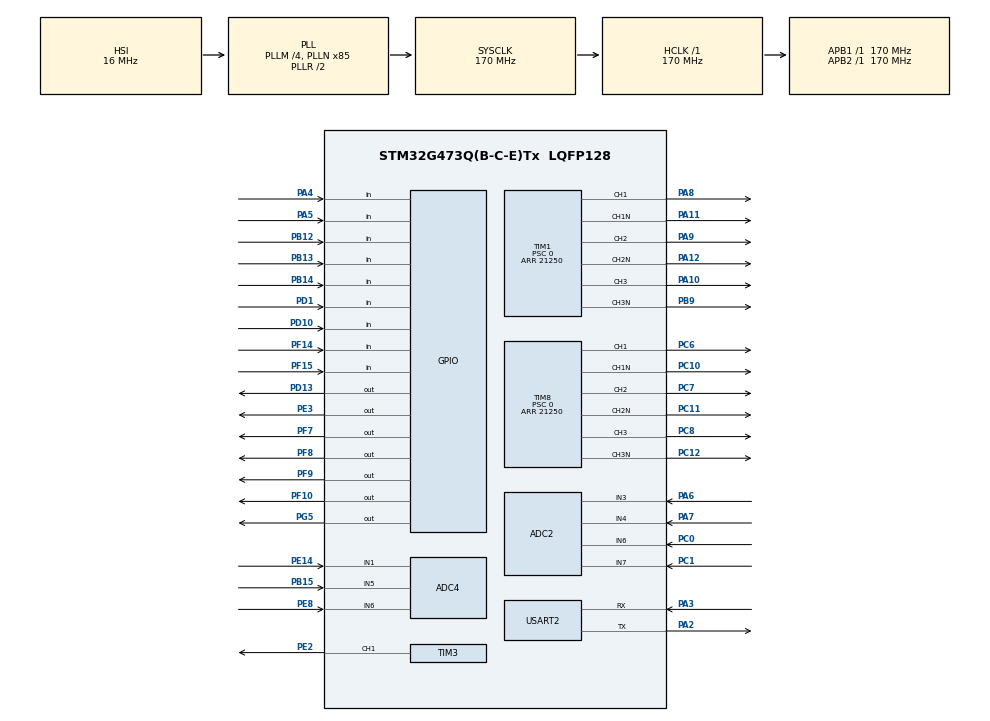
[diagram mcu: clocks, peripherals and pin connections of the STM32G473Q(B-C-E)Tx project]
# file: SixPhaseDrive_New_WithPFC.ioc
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ADC2.DMAContinuousRequests=DISABLE
ADC2.EOCSelection=ADC_EOC_SINGLE_CONV
ADC2.EnableInjectedConversion=ENABLE
ADC2.EnableRegularConversion=DISABLE
ADC2.ExternalTrigInjecConv=ADC_EXTERNALTRIGINJEC_T1_TRGO
ADC2.InjNumberOfConversion=4
ADC2.InjectedChannel-10\#ChannelInjectedConversion=ADC_CHANNEL_3
ADC2.InjectedChannel-11\#ChannelInjectedConversion=ADC_CHANNEL_7
ADC2.InjectedChannel-12\#ChannelInjectedConversion=ADC_CHANNEL_4
ADC2.InjectedChannel-9\#ChannelInjectedConversion=ADC_CHANNEL_6
ADC2.InjectedOffsetNumber-10\#ChannelInjectedConversion=ADC_OFFSET_NONE
ADC2.InjectedOffsetNumber-11\#ChannelInjectedConversion=ADC_OFFSET_NONE
ADC2.InjectedOffsetNumber-12\#ChannelInjectedConversion=ADC_OFFSET_NONE
ADC2.InjectedOffsetNumber-9\#ChannelInjectedConversion=ADC_OFFSET_NONE
ADC2.InjectedRank-10\#ChannelInjectedConversion=2
ADC2.InjectedRank-11\#ChannelInjectedConversion=3
ADC2.InjectedRank-12\#ChannelInjectedConversion=4
ADC2.InjectedRank-9\#ChannelInjectedConversion=1
ADC2.InjectedSamplingTime-10\#ChannelInjectedConversion=ADC_SAMPLETIME_6CYCLES_5
ADC2.InjectedSamplingTime-11\#ChannelInjectedConversion=ADC_SAMPLETIME_6CYCLES_5
ADC2.InjectedSamplingTime-12\#ChannelInjectedConversion=ADC_SAMPLETIME_6CYCLES_5
ADC2.InjectedSamplingTime-9\#ChannelInjectedConversion=ADC_SAMPLETIME_6CYCLES_5
ADC2.Rank4_Channel=ADC_CHANNEL_4
ADC4.Channel-0\#ChannelRegularConversion=ADC_CHANNEL_5
ADC4.Channel-1\#ChannelRegularConversion=ADC_CHANNEL_6
ADC4.Channel-2\#ChannelRegularConversion=ADC_CHANNEL_1
ADC4.DMAContinuousRequests=ENABLE
ADC4.EOCSelection=ADC_EOC_SEQ_CONV
ADC4.ExternalTrigConv=ADC_EXTERNALTRIG_T4_TRGO
ADC4.ExternalTrigConvEdge=ADC_EXTERNALTRIGCONVEDGE_FALLING
ADC4.NbrOfConversion=3
ADC4.NbrOfConversionFlag=1
ADC4.OffsetNumber-0\#ChannelRegularConversion=ADC_OFFSET_NONE
ADC4.OffsetNumber-1\#ChannelRegularConversion=ADC_OFFSET_NONE
ADC4.OffsetNumber-2\#ChannelRegularConversion=ADC_OFFSET_NONE
ADC4.Overrun=ADC_OVR_DATA_OVERWRITTEN
ADC4.Rank-0\#ChannelRegularConversion=1
ADC4.Rank-1\#ChannelRegularConversion=2
ADC4.Rank-2\#ChannelRegularConversion=3
ADC4.SamplingTime-0\#ChannelRegularConversion=ADC_SAMPLETIME_12CYCLES_5
ADC4.SamplingTime-1\#ChannelRegularConversion=ADC_SAMPLETIME_12CYCLES_5
ADC4.SamplingTime-2\#ChannelRegularConversion=ADC_SAMPLETIME_12CYCLES_5
Dma.ADC4.0.Direction=DMA_PERIPH_TO_MEMORY
Dma.ADC4.0.EventEnable=DISABLE
Dma.ADC4.0.Instance=DMA1_Channel2
Dma.ADC4.0.MemDataAlignment=DMA_MDATAALIGN_HALFWORD
Dma.ADC4.0.MemInc=DMA_MINC_ENABLE
Dma.ADC4.0.Mode=DMA_CIRCULAR
Dma.ADC4.0.PeriphDataAlignment=DMA_PDATAALIGN_HALFWORD
Dma.ADC4.0.PeriphInc=DMA_PINC_DISABLE
Dma.ADC4.0.Polarity=HAL_DMAMUX_REQ_GEN_RISING
Dma.ADC4.0.Priority=DMA_PRIORITY_VERY_HIGH
Dma.ADC4.0.RequestNumber=1
Dma.ADC4.0.SignalID=NONE
Dma.ADC4.0.SyncEnable=DISABLE
Dma.ADC4.0.SyncPolarity=HAL_DMAMUX_SYNC_NO_EVENT
Dma.ADC4.0.SyncRequestNumber=1
Dma.ADC4.0.SyncSignalID=NONE
Dma.Request0=ADC4
Mcu.Family=STM32G4
Mcu.Name=STM32G473Q(B-C-E)Tx
Mcu.Package=LQFP128
NVIC.ADC1_2_IRQn=true\:3\:0\:true\:true\:true\:2\:true\:true\:true
NVIC.DMA1_Channel2_IRQn=true\:0\:0\:false\:false\:true\:false\:true\:true
NVIC.PriorityGroup=NVIC_PRIORITYGROUP_4
NVIC.TIM1_UP_TIM16_IRQn=true\:2\:0\:true\:true\:true\:1\:true\:true\:true
NVIC.TIM4_IRQn=true\:0\:0\:true\:false\:true\:true\:true\:true
PA10.Signal=S_TIM1_CH3
PA11.Mode=PWM Generation1 CH1 CH1N
PA11.Signal=TIM1_CH1N
PA12.Mode=PWM Generation2 CH2 CH2N
PA12.Signal=TIM1_CH2N
PA13.Mode=Serial_Wire
PA13.Signal=SYS_JTMS-SWDIO
PA14.Mode=Serial_Wire
PA14.Signal=SYS_JTCK-SWCLK
PA2.Mode=Asynchronous
PA2.Signal=USART2_TX
PA3.Mode=Asynchronous
PA3.Signal=USART2_RX
PA4.Signal=GPIO_Input
PA5.Signal=GPIO_Input
PA6.Mode=IN3-Single-Ended
PA6.Signal=ADC2_IN3
PA7.Mode=IN4-Single-Ended
PA7.Signal=ADC2_IN4
PA8.Signal=S_TIM1_CH1
PA9.Signal=S_TIM1_CH2
PB12.Signal=GPIO_Input
PB13.Signal=GPIO_Input
PB14.Signal=GPIO_Input
PB15.Mode=IN5-Single-Ended
PB15.Signal=ADC4_IN5
PB9.Mode=PWM Generation3 CH3 CH3N
PB9.Signal=TIM1_CH3N
PC0.Mode=IN6-Single-Ended
PC0.Signal=ADC2_IN6
PC1.Mode=IN7-Single-Ended
PC1.Signal=ADC2_IN7
PC10.Mode=PWM Generation1 CH1 CH1N
PC10.Signal=TIM8_CH1N
PC11.Mode=PWM Generation2 CH2 CH2N
PC11.Signal=TIM8_CH2N
PC12.Mode=PWM Generation3 CH3 CH3N
PC12.Signal=TIM8_CH3N
PC14-OSC32_IN.Mode=LSE-External-Oscillator
PC14-OSC32_IN.Signal=RCC_OSC32_IN
PC15-OSC32_OUT.Mode=LSE-External-Oscillator
PC15-OSC32_OUT.Signal=RCC_OSC32_OUT
PC6.Signal=S_TIM8_CH1
PC7.Signal=S_TIM8_CH2
PC8.Signal=S_TIM8_CH3
PD1.Signal=GPIO_Input
PD10.Signal=GPIO_Input
PD13.Signal=GPIO_Output
PE14.Mode=IN1-Single-Ended
PE14.Signal=ADC4_IN1
PE2.Signal=S_TIM3_CH1
PE3.Signal=GPIO_Output
PE8.Mode=IN6-Single-Ended
PE8.Signal=ADC4_IN6
PF0-OSC_IN.Mode=HSE-External-Oscillator
PF0-OSC_IN.Signal=RCC_OSC_IN
PF1-OSC_OUT.Mode=HSE-External-Oscillator
PF1-OSC_OUT.Signal=RCC_OSC_OUT
PF10.Signal=GPIO_Output
PF14.Signal=GPIO_Input
PF15.Signal=GPIO_Input
PF7.Signal=GPIO_Output
PF8.Signal=GPIO_Output
PF9.Signal=GPIO_Output
PG5.Signal=GPIO_Output
ProjectManager.HeapSize=0x200
ProjectManager.StackSize=0x400
ProjectManager.TargetToolchain=STM32CubeIDE
RCC.ADC12Freq_Value=170000000
RCC.ADC345Freq_Value=170000000
RCC.AHBFreq_Value=170000000
RCC.APB1Freq_Value=170000000
RCC.APB1TimFreq_Value=170000000
RCC.APB2Freq_Value=170000000
RCC.APB2TimFreq_Value=170000000
RCC.CortexFreq_Value=170000000
RCC.EXTERNAL_CLOCK_VALUE=12288000
RCC.HCLKFreq_Value=170000000
RCC.HSE_VALUE=24000000
RCC.HSI48_VALUE=48000000
RCC.HSI_VALUE=16000000
RCC.PLLM=RCC_PLLM_DIV4
RCC.PLLN=85
RCC.SYSCLKFreq_VALUE=170000000
RCC.SYSCLKSource=RCC_SYSCLKSOURCE_PLLCLK
RCC.USBFreq_Value=170000000
RCC.VCOOutputFreq_Value=340000000
SH.S_TIM1_CH1.0=TIM1_CH1,PWM Generation1 CH1 CH1N
SH.S_TIM1_CH2.0=TIM1_CH2,PWM Generation2 CH2 CH2N
SH.S_TIM1_CH3.0=TIM1_CH3,PWM Generation3 CH3 CH3N
SH.S_TIM3_CH1.0=TIM3_CH1,PWM Generation1 CH1
SH.S_TIM8_CH1.0=TIM8_CH1,PWM Generation1 CH1 CH1N
SH.S_TIM8_CH2.0=TIM8_CH2,PWM Generation2 CH2 CH2N
SH.S_TIM8_CH3.0=TIM8_CH3,PWM Generation3 CH3 CH3N
TIM1.Channel-PWM\ Generation1\ CH1\ CH1N=TIM_CHANNEL_1
TIM1.Channel-PWM\ Generation2\ CH2\ CH2N=TIM_CHANNEL_2
TIM1.Channel-PWM\ Generation3\ CH3\ CH3N=TIM_CHANNEL_3
TIM1.CounterMode=TIM_COUNTERMODE_CENTERALIGNED3
TIM1.DeadTime=170
TIM1.OCMode_PWM-PWM\ Generation1\ CH1\ CH1N=TIM_OCMODE_PWM1
TIM1.OCMode_PWM-PWM\ Generation2\ CH2\ CH2N=TIM_OCMODE_PWM1
TIM1.OCMode_PWM-PWM\ Generation3\ CH3\ CH3N=TIM_OCMODE_PWM1
TIM1.OCNIdleState_1=TIM_OCNIDLESTATE_RESET
TIM1.OCNIdleState_2=TIM_OCNIDLESTATE_RESET
TIM1.OCNIdleState_3=TIM_OCNIDLESTATE_RESET
TIM1.OCNPolarity_1=TIM_OCNPOLARITY_HIGH
TIM1.OCNPolarity_2=TIM_OCNPOLARITY_HIGH
TIM1.OCNPolarity_3=TIM_OCNPOLARITY_HIGH
TIM1.PeriodNoDither=21250
TIM1.Prescaler=0
TIM1.RepetitionCounter=1
TIM1.TIM_MasterOutputTrigger=TIM_TRGO_UPDATE
TIM3.Channel-PWM\ Generation1\ CH1=TIM_CHANNEL_1
TIM3.PeriodNoDither=2297
TIM3.TIM_MasterOutputTrigger=TIM_TRGO_UPDATE
TIM4.Channel-PWM\ Generation1\ No\ Output=TIM_CHANNEL_1
TIM4.PeriodNoDither=2297
TIM4.Prescaler=3
TIM4.TIM_MasterOutputTrigger=TIM_TRGO_UPDATE
TIM8.Channel-PWM\ Generation1\ CH1\ CH1N=TIM_CHANNEL_1
TIM8.Channel-PWM\ Generation2\ CH2\ CH2N=TIM_CHANNEL_2
TIM8.Channel-PWM\ Generation3\ CH3\ CH3N=TIM_CHANNEL_3
TIM8.CounterMode=TIM_COUNTERMODE_CENTERALIGNED3
TIM8.DeadTime=170
TIM8.OCIdleState_3=TIM_OCIDLESTATE_RESET
TIM8.OCMode_PWM-PWM\ Generation1\ CH1\ CH1N=TIM_OCMODE_PWM1
TIM8.OCMode_PWM-PWM\ Generation2\ CH2\ CH2N=TIM_OCMODE_PWM1
TIM8.OCMode_PWM-PWM\ Generation3\ CH3\ CH3N=TIM_OCMODE_PWM1
TIM8.OCNIdleState_1=TIM_OCNIDLESTATE_RESET
TIM8.OCNIdleState_2=TIM_OCNIDLESTATE_RESET
TIM8.OCNIdleState_3=TIM_OCNIDLESTATE_RESET
TIM8.OCNPolarity_1=TIM_OCNPOLARITY_HIGH
TIM8.OCNPolarity_2=TIM_OCNPOLARITY_HIGH
TIM8.OCNPolarity_3=TIM_OCNPOLARITY_HIGH
TIM8.PeriodNoDither=21250
TIM8.Prescaler=0
TIM8.RepetitionCounter=1
TIM8.TIM_MasterOutputTrigger=TIM_TRGO_UPDATE
USART2.VirtualMode-Asynchronous=VM_ASYNC
VP_SYS_VS_DBSignals.Mode=DisableDeadBatterySignals
VP_TIM1_VS_ClockSourceINT.Mode=Internal
VP_TIM3_VS_ClockSourceINT.Mode=Internal
VP_TIM4_VS_ClockSourceINT.Mode=Internal
VP_TIM4_VS_no_output1.Mode=PWM Generation1 No Output
VP_TIM8_VS_ClockSourceITR.Mode=TriggerSource_ITR0
VP_TIM8_VS_ControllerModeTrigger.Mode=Trigger Mode
board=custom

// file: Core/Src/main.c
/* USER CODE BEGIN Header */
/**
  ******************************************************************************
  * @file           : main.c
  * @brief          : Main program body
  ******************************************************************************
  * @attention
  *
  * Copyright (c) 2024 STMicroelectronics.
  * All rights reserved.
  *
  * This software is licensed under terms that can be found in the LICENSE file
  * in the root directory of this software component.
  * If no LICENSE file comes with this software, it is provided AS-IS.
  *
  ******************************************************************************
  */
/* USER CODE END Header */
#include "main.h"

/* USER CODE BEGIN Includes */
#include <string.h>
#include <math.h>
#include <stdlib.h>
#include <clarke.h>
#include <vsd.h>
#include <ivsd.h>
#include <ipark.h>
#include <park.h>
#include <ramp_gen.h>
#include <rampctrl.h>
#include <svgen.h>
#include <Vhz_profile.h>
#include <pid.h>
#include <piq.h>
#include <pi.h>
#include <pi_spd.h>
#include <PhaseVoltage.h>
#include <DataLogger.h>
#include <fluxObs.h>
#include <fluxObs_const.h>
#include <speed_est.h>
#include <speed_const.h>
#include "PFC_control.h"

/* USER CODE END Includes */

/* USER CODE BEGIN PD */
#define TBPRD_PWM 21250                       // 10 kHz        Up-down count mode for TIM1 with controlling the PWM.
#define HALF_TBPRD_PWM 10625                  // 10 kHz
#define Fs 4000                             // Switching frequency
#define T 0.00025                             // Sampling Period
#define PI 3.14159265358979
#define Oneby2PI 0.15915494

#define VBASE 		380                           // Base Voltage : Vdc/sqrt(3)
#define IBASE 		10                            // Base Current
#define FBASE 		100                           // Base Frequency
#define INV_FBASE 	0.01                           // 1/FBASE
#define INV_IBASE   0.1                           // 1/IBASE

#define RS 			1.15                               // Stator resistance
#define RR 			1.20                               // Rotor Resistance
#define LS 			0.114                             // Stator Inductance
#define LR 			0.114                             // Rotor Inductance
#define LM 			0.105                             // Magnetizing Inductance
#define POLES   	6

//#define RS 			2.5                               // Stator resistance
//#define RR 			1.31                               // Rotor Resistance
//#define LS 			0.265                             // Stator Inductance
//#define LR 			0.265                             // Rotor Inductance
//#define LM 			0.256                             // Magnetizing Inductance
//#define POLES   	4

#define IBUFF_SIZE 1000
#define FBUFF_SIZE 1000

#define MODE_1 1                 // Double Scalar Control
#define MODE_2 2                 // VSD Scalar Control
#define MODE_3 3                 // Dual Vector Control
#define MODE_4 4                 // VSD Control
#define MODE_5 5                 // Dual I/F Control
#define MODE_6 6                 // VSD  I/F Control

#define MODE MODE_1

#ifndef MODE
#error Define MODE OF OPERATION!!!
#endif

/* USER CODE END PD */

ADC_HandleTypeDef hadc2;
ADC_HandleTypeDef hadc4;
DMA_HandleTypeDef hdma_adc4;

TIM_HandleTypeDef htim1;
TIM_HandleTypeDef htim3;
TIM_HandleTypeDef htim4;
TIM_HandleTypeDef htim8;

UART_HandleTypeDef huart2;

/* USER CODE BEGIN PV */
uint32_t ADC2_buffer[4];   // Motor Phase Currents

volatile uint16_t Inj_A1 = 0;
volatile uint16_t Inj_B1 = 0;
volatile uint16_t Inj_A2 = 0;
volatile uint16_t Inj_B2 = 0;

DATA_LOG_4CH_INT dLogInt;
DATA_LOG_4CH_FLOAT dLogFloat;
int16_t iBuff1[IBUFF_SIZE];
int16_t iBuff2[IBUFF_SIZE];
int16_t iBuff3[IBUFF_SIZE];
int16_t iBuff4[IBUFF_SIZE];
float fBuff1[FBUFF_SIZE];
float fBuff2[FBUFF_SIZE];
float fBuff3[FBUFF_SIZE];
float fBuff4[FBUFF_SIZE];
uint16_t clear_screen, print_log;

// User defined Variables
uint16_t Enable = 0;
uint16_t counter = 0;
uint16_t mode = 1;
uint16_t Activate = 0;
uint16_t SpeedLoopCount = 1;
uint16_t ClosedCurrent = 0;
uint16_t ClosedSpeed = 0;

float user_freq = 10;
float user_current = 0.5;
float mod_index = 0.1;
float mod = 1;
float Vd = 0;
float Vq = 0;
float Valpha = 0;
float Vbeta = 0;
float freq_pu = 0.0;
float F_rate_up = 0.02;
float phase_shift = PI/6;

const float TwoPI = 2.0f*M_PI;

float Trig = 1.0;

// Sensor Offsets and Gains (Calibrated Using Experiments)
float Three3VBy4095 = 0.000805 ;
float V_Offset = -1.5;
float Slope_A1 = 0.1206f ;
float Slope_B1 = 0.1218f;
float Slope_A2 = 0.1222f;
float Slope_B2 = 0.1199f;

float VDC_Slope = - 0.4032;
float VDC_Intercept = 690.37;

// Control Variables
uint32_t pwm_cnt =1;
uint32_t pfc_cnt = 1;
uint16_t pfc_control_run=0;
uint16_t enable_voltage_closed_loop=0;
uint16_t SpeedLoopPrescaler = 10;
float A1_INT,B1_INT,A2_INT,B2_INT;
float A1,B1,C1,A2,B2,C2;
float Vdc;
float Angle,Angle1,Angle2,Angle6;
float Alpha, Beta,X,Y;

float IdRef = 0.3;                            // 30 percent of nominal current
float IqRef = 0.0;

// Controller Gains
float Kpp = 0.001;
float Kii = 0.1;

float Kpx = 0.001;
float Kix = 0.1;

float Kpw = 1.0;
float Kiw = 0.0005;

//Per unit Values
float Z_base,Phi_base,L_base,W_base,R_pu,Ls_pu;

uint32_t cnt = 1;

//PFC variables
//junk

//**********************//
float Vac_filtered, Vac_RMS, VacPK_inv,Vdc_filtered, Vburst_H, Vburst_L, Vac_RMS_real;
float Vdc,IL, Vac,IA,IB,IC,NTC_temp;
float VdcRef, VdcTarget = 120, ev, DemandCurrent,DemandCurrentMAX = 1500,dVref = 0.000302265f, Vary_Vc =150.0;  // 1 corresponds to 3.7 V/s
float NTC_Precharge, Vdc_Trip, IL_Trip, IL_ref;
float ei, pwm_cmd, pwm_cmd_debug, Vc, duty_PFC;

const float IL_calibration = 1.0f;
const float Vac_calibration = 1.0f; //0.823f;
const float Vdc_calibration = 1.0f;

volatile uint16_t Vdc_INT,Vac_INT,IL_INT,IA_INT,IB_INT,IC_INT, Temp_INT, Uu_INT, Uv_INT, Uw_INT, OverCurrent_INT;
volatile uint16_t ADC4_buffer[ADC_BUF_SIZE];
volatile uint32_t ADC_buffer2[ADC_BUF_SIZE-1];

uint16_t enable_closed_loop=0;
uint16_t enable_PFC_burst_mode = 0;
uint16_t pfc_DC_control_run=0;
uint16_t pwm_cmd_uint;

int enable_OCD = 0, CurrProtection_ON = 0, VolProtection_ON = 0, prot_var = 0, NTC_locked = 0;

//*********************** PFC Controlelr gains ***************
#define Vac_b0     0.000009807882855712//0.00006092
#define Vac_b1     0.000019615765711424//0.00012184
#define Vac_b2     0.000009807882855712//0.00006092
#define Vac_a1    -1.987472984166555//-1.9751
#define Vac_a2     0.987512215697978//0.9753

// current compensator gains, NEW Current compensator
#define CI_b0      0.044365534154009
#define CI_b1      -0.018039365595791
#define CI_b2      0.001176812183666
#define CI_a1      -0.451535753739813
#define CI_a2      -0.543225583261733

//voltage compensator gains
#define CV_b0     0.107379952051721  //0.099376577815668
#define CV_b1     0.000364078028194  //0.000311711092166
#define CV_b2     -0.107015874023527 //-0.099064866723502
#define CV_a1     -1.983161391196042 //-1.9844144453917
#define CV_a2     0.983161391196042  //0.9844144453917
// Notch filter gains (50Hz)
#define Notch_b0    0.9849830  // 0.9860932
#define Notch_b1    -1.9687630 // -1.9711512
#define Notch_b2    0.9849160  // 0.9860312
#define Notch_a1    -1.9687630 // -1.9711512
#define Notch_a2    0.9698990  // 0.9721243

//***************************protection init***********************************
int Read_EARTH_Fault, Read_SC_Fault, Read_OC_Fault, Read_OnOff_Control;
int OCfault_Flag, count_SCFault, EM_Stop, count_EarthFault ;
//**************************************************************
// Display variables
extern DATA_LOG_4CH_INT dLogInt;
extern DATA_LOG_4CH_FLOAT dLogFloat;

// Initialize MACROS

RAMPGEN rg1 = RAMPGEN_DEFAULTS;
RMPCNTL rc1 = RMPCNTL_DEFAULTS;
VSD vsd1 = VSD_DEFAULTS;
IVSD ivsd1 = IVSD_DEFAULTS;
CLARKE clarke1 = CLARKE_DEFAULTS;
CLARKE clarke2 = CLARKE_DEFAULTS;
PARK   park1   = PARK_DEFAULTS;
PARK   park2   = PARK_DEFAULTS;
IPARK  ipark1  = IPARK_DEFAULTS;
IPARK  ipark2  = IPARK_DEFAULTS;
SVGEN svgen1 = SVGEN_DEFAULTS;
SVGEN svgen2 = SVGEN_DEFAULTS;
VHZPROF vhz1 = VHZPROF_DEFAULTS;
PHASEVOLTAGE volt1 = PHASEVOLTAGE_DEFAULTS;
PHASEVOLTAGE volt2 = PHASEVOLTAGE_DEFAULTS;
PI_CONTROLLER pi_id1 = PI_CONTROLLER_DEFAULTS;
PI_CONTROLLER pi_iq1 = PI_CONTROLLER_DEFAULTS;
PI_CONTROLLER pi_id2 = PI_CONTROLLER_DEFAULTS;
PI_CONTROLLER pi_iq2 = PI_CONTROLLER_DEFAULTS;
PI_CONTROLLER pi_id = PI_CONTROLLER_DEFAULTS;
PI_CONTROLLER pi_iq = PI_CONTROLLER_DEFAULTS;
PI_CONTROLLER pi_ix = PI_CONTROLLER_DEFAULTS;
PI_CONTROLLER pi_iy = PI_CONTROLLER_DEFAULTS;
PI_SPD_CONTROLLER pi_spd = PI_SPD_CONTROLLER_DEFAULTS;
FLUX_OBS flux1 = FLUXOBS_DEFAULTS;
FLUXOBS_CONST flux_const1 = FLUXOBS_CONST_DEFAULTS;
SPEEDEST speed1 = SPEEDEST_DEFAULTS;
SPEED_CONST speed_const1 = SPEED_CONST_DEFAULTS;
DF22 testDF22filter;
DF22 NotchFilter;
DF22 CurrentCompensator;
DF22 DCVoltageCompensator;

/* USER CODE END PV */

void SystemClock_Config(void);
static void MX_GPIO_Init(void);
static void MX_DMA_Init(void);
static void MX_TIM1_Init(void);
static void MX_TIM8_Init(void);
static void MX_USART2_UART_Init(void);
static void MX_ADC2_Init(void);
static void MX_TIM4_Init(void);
static void MX_TIM3_Init(void);
static void MX_ADC4_Init(void);
static void MX_NVIC_Init(void);
/* USER CODE BEGIN PFP */
void PWM_start(void);
void PWM_stop(void);
void PFC_PWM_start(void);
void PFC_PWM_stop(void);
void UARTCommands(void);
/* USER CODE END PFP */

/* USER CODE BEGIN 0 */
uint8_t buf[12];
uint8_t msg[32];
uint8_t num[6];
uint8_t TXbuffer[50];
uint8_t received;
unsigned char* msg2;
uint8_t buffer[10];
unsigned char* display_number;
float PWM_PFC_duty, duty;
uint16_t ramp_duty=0, no_fault = 0, OC_var = 1, IsRelayOn = 0, PFC_PWM = 0;
int16_t trigger=0;
float trigger_float=0;
float EM_SD_Status;
void PrintScreen(void);
void printDataLog(int16_t *DataBuffer1, int16_t *DataBuffer2, int16_t *DataBuffer3, int16_t *DataBuffer4, uint16_t dataBufferLength, uint16_t *start);
void runVDCramp(void);
void Check_OCFault(void) ;

/* USER CODE END 0 */

int main(void)
{

  /* USER CODE BEGIN 1 */
	vhz1.VoltMax = 1.0;
	vhz1.VoltMin = 0.01;
	vhz1.HighFreq = 0.9;
	vhz1.LowFreq = 0.05;
	vhz1.FreqMax = 1.0;

	rc1.Tstep = T*rc1.RampDelayMax*F_rate_up;
	rg1.StepAngleMax = FBASE*T;

// Initialize motor parameters for flux observer
	flux_const1.Rs = RS;
	flux_const1.Rr = RR;
	flux_const1.Ls = LS;
	flux_const1.Lr = LR;
	flux_const1.Lm = LM;
	flux_const1.Vb = VBASE;
	flux_const1.Ib = IBASE;
	flux_const1.Ts = T;
	FLUXOBS_CONST_MACRO(flux_const1)

// 	Initialize constants for flux observer
	flux1.K1 = flux_const1.K1;
	flux1.K2 = flux_const1.K2;
	flux1.K3 = flux_const1.K3;
	flux1.K4 = flux_const1.K4;
	flux1.K5 = flux_const1.K5;
	flux1.K6 = flux_const1.K6;
	flux1.K7 = flux_const1.K7;
	flux1.K8 = flux_const1.K8;
	flux1.Kp = 0.05;
	flux1.Ki = 0.1;

	// 	Initialize constants for speed estimation

	speed_const1.Rr = RR;
	speed_const1.Lr = LR;
	speed_const1.fb = FBASE;
	speed_const1.fc = 0.5;
	speed_const1.Ts = T;
	SPEED_CONST_MACRO(speed_const1)

	// Initialize parameters for speed estimation

	speed1.K1 = speed_const1.K1;
	speed1.K2 = speed_const1.K2;
	speed1.K3 = speed_const1.K3;
	speed1.K4 = speed_const1.K4;
	speed1.BaseRpm = 120*FBASE/POLES;

	pi_spd.Ki = Kiw;
	pi_spd.Kp = Kpw;
	pi_spd.Umax = 0.8;
	pi_spd.Umin = -0.8;

	pi_id1.Ki = Kii;
	pi_id1.Kp = Kpp;
	pi_id1.Umax = 0.8;
    pi_id1.Umin = -0.8;

    pi_iq1.Ki = Kii;
    pi_iq1.Kp = Kpp;
    pi_iq1.Umax = 0.8;
    pi_iq1.Umin = -0.8;

	pi_id2.Ki = Kii;
	pi_id2.Kp = Kpp;
	pi_id2.Umax = 0.8;
	pi_id2.Umin = -0.8;

	pi_iq2.Ki = Kii;
	pi_iq2.Kp = Kpp;
	pi_iq2.Umax = 0.8;
	pi_iq2.Umin = -0.8;

	pi_id.Ki = Kii;
	pi_id.Kp = Kpp;
	pi_id.Umax = 0.8;
    pi_id.Umin = -0.8;

    pi_iq.Ki = Kii;
    pi_iq.Kp = Kpp;
    pi_iq.Umax = 0.8;
    pi_iq.Umin = -0.8;

    pi_ix.Ki = Kix;
	pi_ix.Kp = Kpx;
	pi_ix.Umax = 0.5;
	pi_ix.Umin = -0.5;

	pi_iy.Ki = Kix;
	pi_iy.Kp = Kpx;
	pi_iy.Umax = 0.5;
	pi_iy.Umin = -0.5;

//	W_base = 2*PI*FBASE;
//	Z_base = VBASE/IBASE;
//	Phi_base = VBASE/W_base;
//	L_base = Z_base/W_base;
//	Ls_pu = Ls/L_base;
//	R_pu = Rs/Z_base;

//	pi_id1.Ki = R_pu/Ls_pu;
//	pi_id1.Kp = 0.1*Ls_pu*2*PI*Fs/15/W_base;

  // Initialize the PI module for Id
  /* USER CODE END 1 */

  /* MCU Configuration--------------------------------------------------------*/

  /* Reset of all peripherals, Initializes the Flash interface and the Systick. */
  HAL_Init();

  /* Configure the system clock */
  SystemClock_Config();

  /* Initialize all configured peripherals */
  MX_GPIO_Init();
  MX_DMA_Init();
  MX_TIM1_Init();
  MX_TIM8_Init();
  MX_USART2_UART_Init();
  MX_ADC2_Init();
  MX_TIM4_Init();
  MX_TIM3_Init();
  MX_ADC4_Init();

  /* Initialize interrupts */
  MX_NVIC_Init();
  /* USER CODE BEGIN 2 */

  DATA_LOG_4CH_FLOAT_config(&dLogFloat,
                                     &ivsd1.As1,
                                     &pi_id.Fbk,
                                     &pi_spd.Out,
                                     &pi_iq.Fbk,
   									fBuff1,
   									fBuff2,
   									fBuff3,
   									fBuff4,
   									FBUFF_SIZE,
                                       0.5,    //trigger
                                       1    // preScalar
                                       );

 DATA_LOG_4CH_INT_config(&dLogInt,
								&ivsd1.As1,
								&pi_id.Fbk,
								&pi_spd.Out,
								&pi_iq.Fbk,
								iBuff1,
								iBuff2,
								iBuff3,
								iBuff4,
								IBUFF_SIZE,
								   1, //trigger
								   1 // preScalar
								   );

 //PFC controller variables
 InitFilterDF22(&testDF22filter,Vac_b0,Vac_b1,Vac_b2,Vac_a1,Vac_a2);
 InitFilterDF22(&CurrentCompensator,CI_b0,CI_b1,CI_b2,CI_a1,CI_a2);
 InitFilterDF22(&NotchFilter,Notch_b0,Notch_b1,Notch_b2,Notch_a1,Notch_a2);
 InitFilterDF22(&DCVoltageCompensator,CV_b0,CV_b1,CV_b2,CV_a1,CV_a2);

  clear_screen=1;

  HAL_TIM_Base_Start_IT(&htim1);
 // HAL_TIM_Base_Start_IT(&htim15);
  HAL_TIM_Base_Start_IT(&htim4);

  //HAL_ADC_Start_DMA(&hadc2, ADC2_buffer, 4);
 // HAL_ADC_Start_DMA(&hadc4, ADC4_buffer, 3); //PFC

  if(HAL_OK != HAL_ADCEx_Calibration_Start(&hadc4, ADC_SINGLE_ENDED)) Error_Handler();
  if(HAL_OK != HAL_ADC_Start_DMA(&hadc4, (uint32_t*)ADC4_buffer, ADC_BUF_SIZE)) Error_Handler();//Start ADC4 with DMA

  HAL_ADCEx_InjectedStart_IT(&hadc2); // Start Motor ADC Conversion (Injected Channel, Tim1-PWM-Triggered, Interrupt Mode)

  HAL_TIM_PWM_Start(&htim1, TIM_CHANNEL_1);
  HAL_TIMEx_PWMN_Start(&htim1, TIM_CHANNEL_1);
  HAL_TIM_PWM_Start(&htim1, TIM_CHANNEL_2);
  HAL_TIMEx_PWMN_Start(&htim1, TIM_CHANNEL_2);
  HAL_TIM_PWM_Start(&htim1, TIM_CHANNEL_3);
  HAL_TIMEx_PWMN_Start(&htim1, TIM_CHANNEL_3);

  HAL_TIM_PWM_Start(&htim8, TIM_CHANNEL_1);
  HAL_TIMEx_PWMN_Start(&htim8, TIM_CHANNEL_1);
  HAL_TIM_PWM_Start(&htim8, TIM_CHANNEL_2);
  HAL_TIMEx_PWMN_Start(&htim8, TIM_CHANNEL_2);
  HAL_TIM_PWM_Start(&htim8, TIM_CHANNEL_3);
  HAL_TIMEx_PWMN_Start(&htim8, TIM_CHANNEL_3);

  /*-------------- PFC init begin----------------------------*/
  Vc=Vary_Vc ;
  VdcRef=90.0f;
//  VdcTarget_init=120 ; //380.0f;
  IL_Trip = -30;
  //dVref=1.0f; // VDC ramp rate
 // DemandCurrentMAX=1500;        //9500.0;
  NTC_Precharge = 250.0; // 250dc-150V forNTC
  Vdc_Trip = 350.0;
  Vburst_H = 400.0;
  Vburst_L = 370.0;
  enable_closed_loop=0;
  enable_voltage_closed_loop=0;
  /*-------------- PFC init end----------------------------*/

  //****************** GPIO settings for protection *************************
  HAL_GPIO_WritePin(GPIOD, GPIO_PIN_13, GPIO_PIN_SET);   //PD13- EM_STOP_SD - high for IPM to be on, if low then its fault
  HAL_GPIO_WritePin(GPIOD, GPIO_PIN_1, GPIO_PIN_RESET);  // OC_fault
  HAL_GPIO_WritePin(GPIOF, GPIO_PIN_14, GPIO_PIN_RESET); // SC_fault
  HAL_GPIO_WritePin(GPIOF, GPIO_PIN_15, GPIO_PIN_RESET); // Earth_fault
  HAL_GPIO_WritePin(GPIOD, GPIO_PIN_10, GPIO_PIN_RESET);  // on off

  /* USER CODE END 2 */

  /* Infinite loop */
  while (1)
  {

    /* USER CODE BEGIN 3 */

	    pi_spd.Ki = Kiw; 	pi_spd.Kp = Kpw;

		pi_id1.Ki = Kii; 	pi_id1.Kp = Kpp;
		pi_iq1.Ki = Kii; 	pi_iq1.Kp = Kpp;

		pi_id2.Ki = Kii; 	pi_id2.Kp = Kpp;
		pi_iq2.Ki = Kii; 	pi_iq2.Kp = Kpp;

		pi_id.Ki = Kii;		pi_id.Kp = Kpp;
		pi_iq.Ki = Kii;		pi_iq.Kp = Kpp;

		pi_ix.Ki = Kix;		pi_ix.Kp = Kpx;
		pi_iy.Ki = Kix;		pi_iy.Kp = Kpp;

	  if(print_log)
	 	 {
	 	  	printDataLog(iBuff1, iBuff2, iBuff3, iBuff4, IBUFF_SIZE, &print_log);
	 	 }
	 else PrintScreen();

/*-------------- PFC init begin----------------------------*/
	//  if((Vdc>NTC_Precharge/*2376*/) && (NTC_locked == 0)) // relay threshold for bypassing relay in PFC
	  if(IsRelayOn == 1)
	  {
		  HAL_GPIO_WritePin(GPIOE, GPIO_PIN_3, GPIO_PIN_SET); //PE3 - input for NTC, LED off
		  ramp_duty=1;
		//  HAL_Delay(20);
		  NTC_locked = 1;
	  }
	  else
	  {
		  HAL_GPIO_WritePin(GPIOE, GPIO_PIN_3, GPIO_PIN_RESET); //LED ON
	  }
	 // else if (Vdc<150.0f/*1944*/)
//	  {
//		  HAL_GPIO_WritePin(GPIOE, GPIO_PIN_3, GPIO_PIN_RESET);
//		//  duty=0;   // uncomment this for real proto
//		  ramp_duty=0;
//	  }

	  PWM_PFC_duty = (duty*2297.0f);// use constant instead of 2125.0f
	  if(enable_closed_loop==0) __HAL_TIM_SetCompare(&htim3,TIM_CHANNEL_1,PWM_PFC_duty);

//	  if(PFC_PWM == 1)
//	  {
//		  PFC_PWM_start();
//	  }
//	  else PFC_PWM_stop();

	  /*-------------- protections ----------------------------*/
	   Check_OCFault() ; //OC fault detection

////PD10 for on off control
	  Read_OnOff_Control = HAL_GPIO_ReadPin(GPIOD, GPIO_PIN_10) ; // 1- on off switch is off, 0-on off switch is on

//	  if (Read_OnOff_Control == 1)
//	  {
//		  PWM_stop();  //MCU stops PWM
//	  }

	  //enable this to test fault
	  if (EM_Stop)
	  {
		  HAL_GPIO_WritePin(GPIOD, GPIO_PIN_13, GPIO_PIN_RESET); //IPM_stops here
	  }

	  /*-------------- protection end ----------------------------*/

	  UARTCommands();

	  if(Vac_RMS>30.0) VacPK_inv= 0.5/Vac_RMS;//0.707106781/Vac_RMS;
/*-------------- PFC init end----------------------------*/

	 HAL_Delay(300);

  }
  /* USER CODE END 3 */
}

void SystemClock_Config(void)
{
  RCC_OscInitTypeDef RCC_OscInitStruct = {0};
  RCC_ClkInitTypeDef RCC_ClkInitStruct = {0};

  /** Configure the main internal regulator output voltage
  */
  HAL_PWREx_ControlVoltageScaling(PWR_REGULATOR_VOLTAGE_SCALE1_BOOST);

  /** Initializes the RCC Oscillators according to the specified parameters
  * in the RCC_OscInitTypeDef structure.
  */
  RCC_OscInitStruct.OscillatorType = RCC_OSCILLATORTYPE_HSI;
  RCC_OscInitStruct.HSIState = RCC_HSI_ON;
  RCC_OscInitStruct.HSICalibrationValue = RCC_HSICALIBRATION_DEFAULT;
  RCC_OscInitStruct.PLL.PLLState = RCC_PLL_ON;
  RCC_OscInitStruct.PLL.PLLSource = RCC_PLLSOURCE_HSI;
  RCC_OscInitStruct.PLL.PLLM = RCC_PLLM_DIV4;
  RCC_OscInitStruct.PLL.PLLN = 85;
  RCC_OscInitStruct.PLL.PLLP = RCC_PLLP_DIV2;
  RCC_OscInitStruct.PLL.PLLQ = RCC_PLLQ_DIV2;
  RCC_OscInitStruct.PLL.PLLR = RCC_PLLR_DIV2;
  if (HAL_RCC_OscConfig(&RCC_OscInitStruct) != HAL_OK)
  {
    Error_Handler();
  }

  /** Initializes the CPU, AHB and APB buses clocks
  */
  RCC_ClkInitStruct.ClockType = RCC_CLOCKTYPE_HCLK|RCC_CLOCKTYPE_SYSCLK
                              |RCC_CLOCKTYPE_PCLK1|RCC_CLOCKTYPE_PCLK2;
  RCC_ClkInitStruct.SYSCLKSource = RCC_SYSCLKSOURCE_PLLCLK;
  RCC_ClkInitStruct.AHBCLKDivider = RCC_SYSCLK_DIV1;
  RCC_ClkInitStruct.APB1CLKDivider = RCC_HCLK_DIV1;
  RCC_ClkInitStruct.APB2CLKDivider = RCC_HCLK_DIV1;

  if (HAL_RCC_ClockConfig(&RCC_ClkInitStruct, FLASH_LATENCY_4) != HAL_OK)
  {
    Error_Handler();
  }
}

/**
  * @brief NVIC Configuration.
  * @retval None
  */
static void MX_NVIC_Init(void)
{
  /* TIM1_UP_TIM16_IRQn interrupt configuration */
  HAL_NVIC_SetPriority(TIM1_UP_TIM16_IRQn, 2, 0);
  HAL_NVIC_EnableIRQ(TIM1_UP_TIM16_IRQn);
  /* ADC1_2_IRQn interrupt configuration */
  HAL_NVIC_SetPriority(ADC1_2_IRQn, 3, 0);
  HAL_NVIC_EnableIRQ(ADC1_2_IRQn);
}

static void MX_ADC2_Init(void)
{

  ADC_InjectionConfTypeDef sConfigInjected = {0};

  /** Common config
  */
  hadc2.Instance = ADC2;
  hadc2.Init.ClockPrescaler = ADC_CLOCK_SYNC_PCLK_DIV4;
  hadc2.Init.Resolution = ADC_RESOLUTION_12B;
  hadc2.Init.DataAlign = ADC_DATAALIGN_RIGHT;
  hadc2.Init.GainCompensation = 0;
  hadc2.Init.ScanConvMode = ADC_SCAN_ENABLE;
  hadc2.Init.EOCSelection = ADC_EOC_SINGLE_CONV;
  hadc2.Init.LowPowerAutoWait = DISABLE;
  hadc2.Init.ContinuousConvMode = DISABLE;
  hadc2.Init.NbrOfConversion = 1;
  hadc2.Init.DiscontinuousConvMode = DISABLE;
  hadc2.Init.DMAContinuousRequests = DISABLE;
  hadc2.Init.Overrun = ADC_OVR_DATA_PRESERVED;
  hadc2.Init.OversamplingMode = DISABLE;
  if (HAL_ADC_Init(&hadc2) != HAL_OK)
  {
    Error_Handler();
  }

  /** Configure Injected Channel
  */
  sConfigInjected.InjectedChannel = ADC_CHANNEL_6;
  sConfigInjected.InjectedRank = ADC_INJECTED_RANK_1;
  sConfigInjected.InjectedSamplingTime = ADC_SAMPLETIME_6CYCLES_5;
  sConfigInjected.InjectedSingleDiff = ADC_SINGLE_ENDED;
  sConfigInjected.InjectedOffsetNumber = ADC_OFFSET_NONE;
  sConfigInjected.InjectedOffset = 0;
  sConfigInjected.InjectedNbrOfConversion = 4;
  sConfigInjected.InjectedDiscontinuousConvMode = DISABLE;
  sConfigInjected.AutoInjectedConv = DISABLE;
  sConfigInjected.QueueInjectedContext = DISABLE;
  sConfigInjected.ExternalTrigInjecConv = ADC_EXTERNALTRIGINJEC_T1_TRGO;
  sConfigInjected.ExternalTrigInjecConvEdge = ADC_EXTERNALTRIGINJECCONV_EDGE_RISING;
  sConfigInjected.InjecOversamplingMode = DISABLE;
  if (HAL_ADCEx_InjectedConfigChannel(&hadc2, &sConfigInjected) != HAL_OK)
  {
    Error_Handler();
  }

  /** Configure Injected Channel
  */
  sConfigInjected.InjectedChannel = ADC_CHANNEL_3;
  sConfigInjected.InjectedRank = ADC_INJECTED_RANK_2;
  if (HAL_ADCEx_InjectedConfigChannel(&hadc2, &sConfigInjected) != HAL_OK)
  {
    Error_Handler();
  }

  /** Configure Injected Channel
  */
  sConfigInjected.InjectedChannel = ADC_CHANNEL_7;
  sConfigInjected.InjectedRank = ADC_INJECTED_RANK_3;
  if (HAL_ADCEx_InjectedConfigChannel(&hadc2, &sConfigInjected) != HAL_OK)
  {
    Error_Handler();
  }

  /** Configure Injected Channel
  */
  sConfigInjected.InjectedChannel = ADC_CHANNEL_4;
  sConfigInjected.InjectedRank = ADC_INJECTED_RANK_4;
  if (HAL_ADCEx_InjectedConfigChannel(&hadc2, &sConfigInjected) != HAL_OK)
  {
    Error_Handler();
  }

}

static void MX_ADC4_Init(void)
{

  ADC_ChannelConfTypeDef sConfig = {0};

  /** Common config
  */
  hadc4.Instance = ADC4;
  hadc4.Init.ClockPrescaler = ADC_CLOCK_SYNC_PCLK_DIV4;
  hadc4.Init.Resolution = ADC_RESOLUTION_12B;
  hadc4.Init.DataAlign = ADC_DATAALIGN_RIGHT;
  hadc4.Init.GainCompensation = 0;
  hadc4.Init.ScanConvMode = ADC_SCAN_ENABLE;
  hadc4.Init.EOCSelection = ADC_EOC_SEQ_CONV;
  hadc4.Init.LowPowerAutoWait = DISABLE;
  hadc4.Init.ContinuousConvMode = DISABLE;
  hadc4.Init.NbrOfConversion = 3;
  hadc4.Init.DiscontinuousConvMode = DISABLE;
  hadc4.Init.ExternalTrigConv = ADC_EXTERNALTRIG_T4_TRGO;
  hadc4.Init.ExternalTrigConvEdge = ADC_EXTERNALTRIGCONVEDGE_FALLING;
  hadc4.Init.DMAContinuousRequests = ENABLE;
  hadc4.Init.Overrun = ADC_OVR_DATA_OVERWRITTEN;
  hadc4.Init.OversamplingMode = DISABLE;
  if (HAL_ADC_Init(&hadc4) != HAL_OK)
  {
    Error_Handler();
  }

  /** Configure Regular Channel
  */
  sConfig.Channel = ADC_CHANNEL_5;
  sConfig.Rank = ADC_REGULAR_RANK_1;
  sConfig.SamplingTime = ADC_SAMPLETIME_12CYCLES_5;
  sConfig.SingleDiff = ADC_SINGLE_ENDED;
  sConfig.OffsetNumber = ADC_OFFSET_NONE;
  sConfig.Offset = 0;
  if (HAL_ADC_ConfigChannel(&hadc4, &sConfig) != HAL_OK)
  {
    Error_Handler();
  }

  /** Configure Regular Channel
  */
  sConfig.Channel = ADC_CHANNEL_6;
  sConfig.Rank = ADC_REGULAR_RANK_2;
  if (HAL_ADC_ConfigChannel(&hadc4, &sConfig) != HAL_OK)
  {
    Error_Handler();
  }

  /** Configure Regular Channel
  */
  sConfig.Channel = ADC_CHANNEL_1;
  sConfig.Rank = ADC_REGULAR_RANK_3;
  if (HAL_ADC_ConfigChannel(&hadc4, &sConfig) != HAL_OK)
  {
    Error_Handler();
  }

}

static void MX_TIM1_Init(void)
{

  TIM_ClockConfigTypeDef sClockSourceConfig = {0};
  TIM_MasterConfigTypeDef sMasterConfig = {0};
  TIM_OC_InitTypeDef sConfigOC = {0};
  TIM_BreakDeadTimeConfigTypeDef sBreakDeadTimeConfig = {0};

  htim1.Instance = TIM1;
  htim1.Init.Prescaler = 0;
  htim1.Init.CounterMode = TIM_COUNTERMODE_CENTERALIGNED3;
  htim1.Init.Period = 21250;
  htim1.Init.ClockDivision = TIM_CLOCKDIVISION_DIV1;
  htim1.Init.RepetitionCounter = 1;
  htim1.Init.AutoReloadPreload = TIM_AUTORELOAD_PRELOAD_DISABLE;
  if (HAL_TIM_Base_Init(&htim1) != HAL_OK)
  {
    Error_Handler();
  }
  sClockSourceConfig.ClockSource = TIM_CLOCKSOURCE_INTERNAL;
  if (HAL_TIM_ConfigClockSource(&htim1, &sClockSourceConfig) != HAL_OK)
  {
    Error_Handler();
  }
  if (HAL_TIM_PWM_Init(&htim1) != HAL_OK)
  {
    Error_Handler();
  }
  sMasterConfig.MasterOutputTrigger = TIM_TRGO_UPDATE;
  sMasterConfig.MasterOutputTrigger2 = TIM_TRGO2_RESET;
  sMasterConfig.MasterSlaveMode = TIM_MASTERSLAVEMODE_DISABLE;
  if (HAL_TIMEx_MasterConfigSynchronization(&htim1, &sMasterConfig) != HAL_OK)
  {
    Error_Handler();
  }
  sConfigOC.OCMode = TIM_OCMODE_PWM1;
  sConfigOC.Pulse = 0;
  sConfigOC.OCPolarity = TIM_OCPOLARITY_HIGH;
  sConfigOC.OCNPolarity = TIM_OCNPOLARITY_HIGH;
  sConfigOC.OCFastMode = TIM_OCFAST_DISABLE;
  sConfigOC.OCIdleState = TIM_OCIDLESTATE_RESET;
  sConfigOC.OCNIdleState = TIM_OCNIDLESTATE_RESET;
  if (HAL_TIM_PWM_ConfigChannel(&htim1, &sConfigOC, TIM_CHANNEL_1) != HAL_OK)
  {
    Error_Handler();
  }
  if (HAL_TIM_PWM_ConfigChannel(&htim1, &sConfigOC, TIM_CHANNEL_2) != HAL_OK)
  {
    Error_Handler();
  }
  if (HAL_TIM_PWM_ConfigChannel(&htim1, &sConfigOC, TIM_CHANNEL_3) != HAL_OK)
  {
    Error_Handler();
  }
  sBreakDeadTimeConfig.OffStateRunMode = TIM_OSSR_DISABLE;
  sBreakDeadTimeConfig.OffStateIDLEMode = TIM_OSSI_DISABLE;
  sBreakDeadTimeConfig.LockLevel = TIM_LOCKLEVEL_OFF;
  sBreakDeadTimeConfig.DeadTime = 170;
  sBreakDeadTimeConfig.BreakState = TIM_BREAK_DISABLE;
  sBreakDeadTimeConfig.BreakPolarity = TIM_BREAKPOLARITY_HIGH;
  sBreakDeadTimeConfig.BreakFilter = 0;
  sBreakDeadTimeConfig.BreakAFMode = TIM_BREAK_AFMODE_INPUT;
  sBreakDeadTimeConfig.Break2State = TIM_BREAK2_DISABLE;
  sBreakDeadTimeConfig.Break2Polarity = TIM_BREAK2POLARITY_HIGH;
  sBreakDeadTimeConfig.Break2Filter = 0;
  sBreakDeadTimeConfig.Break2AFMode = TIM_BREAK_AFMODE_INPUT;
  sBreakDeadTimeConfig.AutomaticOutput = TIM_AUTOMATICOUTPUT_DISABLE;
  if (HAL_TIMEx_ConfigBreakDeadTime(&htim1, &sBreakDeadTimeConfig) != HAL_OK)
  {
    Error_Handler();
  }
  HAL_TIM_MspPostInit(&htim1);

}

static void MX_TIM3_Init(void)
{

  TIM_ClockConfigTypeDef sClockSourceConfig = {0};
  TIM_MasterConfigTypeDef sMasterConfig = {0};
  TIM_OC_InitTypeDef sConfigOC = {0};

  htim3.Instance = TIM3;
  htim3.Init.Prescaler = 0;
  htim3.Init.CounterMode = TIM_COUNTERMODE_UP;
  htim3.Init.Period = 2297;
  htim3.Init.ClockDivision = TIM_CLOCKDIVISION_DIV1;
  htim3.Init.AutoReloadPreload = TIM_AUTORELOAD_PRELOAD_DISABLE;
  if (HAL_TIM_Base_Init(&htim3) != HAL_OK)
  {
    Error_Handler();
  }
  sClockSourceConfig.ClockSource = TIM_CLOCKSOURCE_INTERNAL;
  if (HAL_TIM_ConfigClockSource(&htim3, &sClockSourceConfig) != HAL_OK)
  {
    Error_Handler();
  }
  if (HAL_TIM_PWM_Init(&htim3) != HAL_OK)
  {
    Error_Handler();
  }
  sMasterConfig.MasterOutputTrigger = TIM_TRGO_UPDATE;
  sMasterConfig.MasterSlaveMode = TIM_MASTERSLAVEMODE_DISABLE;
  if (HAL_TIMEx_MasterConfigSynchronization(&htim3, &sMasterConfig) != HAL_OK)
  {
    Error_Handler();
  }
  sConfigOC.OCMode = TIM_OCMODE_PWM1;
  sConfigOC.Pulse = 0;
  sConfigOC.OCPolarity = TIM_OCPOLARITY_HIGH;
  sConfigOC.OCFastMode = TIM_OCFAST_DISABLE;
  if (HAL_TIM_PWM_ConfigChannel(&htim3, &sConfigOC, TIM_CHANNEL_1) != HAL_OK)
  {
    Error_Handler();
  }
  HAL_TIM_MspPostInit(&htim3);

}

static void MX_TIM4_Init(void)
{

  TIM_ClockConfigTypeDef sClockSourceConfig = {0};
  TIM_MasterConfigTypeDef sMasterConfig = {0};
  TIM_OC_InitTypeDef sConfigOC = {0};

  htim4.Instance = TIM4;
  htim4.Init.Prescaler = 3;
  htim4.Init.CounterMode = TIM_COUNTERMODE_UP;
  htim4.Init.Period = 2297;
  htim4.Init.ClockDivision = TIM_CLOCKDIVISION_DIV1;
  htim4.Init.AutoReloadPreload = TIM_AUTORELOAD_PRELOAD_DISABLE;
  if (HAL_TIM_Base_Init(&htim4) != HAL_OK)
  {
    Error_Handler();
  }
  sClockSourceConfig.ClockSource = TIM_CLOCKSOURCE_INTERNAL;
  if (HAL_TIM_ConfigClockSource(&htim4, &sClockSourceConfig) != HAL_OK)
  {
    Error_Handler();
  }
  if (HAL_TIM_PWM_Init(&htim4) != HAL_OK)
  {
    Error_Handler();
  }
  sMasterConfig.MasterOutputTrigger = TIM_TRGO_UPDATE;
  sMasterConfig.MasterSlaveMode = TIM_MASTERSLAVEMODE_DISABLE;
  if (HAL_TIMEx_MasterConfigSynchronization(&htim4, &sMasterConfig) != HAL_OK)
  {
    Error_Handler();
  }
  sConfigOC.OCMode = TIM_OCMODE_PWM1;
  sConfigOC.Pulse = 0;
  sConfigOC.OCPolarity = TIM_OCPOLARITY_HIGH;
  sConfigOC.OCFastMode = TIM_OCFAST_DISABLE;
  if (HAL_TIM_PWM_ConfigChannel(&htim4, &sConfigOC, TIM_CHANNEL_1) != HAL_OK)
  {
    Error_Handler();
  }

}

static void MX_TIM8_Init(void)
{

  TIM_SlaveConfigTypeDef sSlaveConfig = {0};
  TIM_MasterConfigTypeDef sMasterConfig = {0};
  TIM_OC_InitTypeDef sConfigOC = {0};
  TIM_BreakDeadTimeConfigTypeDef sBreakDeadTimeConfig = {0};

  htim8.Instance = TIM8;
  htim8.Init.Prescaler = 0;
  htim8.Init.CounterMode = TIM_COUNTERMODE_CENTERALIGNED3;
  htim8.Init.Period = 21250;
  htim8.Init.ClockDivision = TIM_CLOCKDIVISION_DIV1;
  htim8.Init.RepetitionCounter = 1;
  htim8.Init.AutoReloadPreload = TIM_AUTORELOAD_PRELOAD_DISABLE;
  if (HAL_TIM_Base_Init(&htim8) != HAL_OK)
  {
    Error_Handler();
  }
  if (HAL_TIM_PWM_Init(&htim8) != HAL_OK)
  {
    Error_Handler();
  }
  sSlaveConfig.SlaveMode = TIM_SLAVEMODE_TRIGGER;
  sSlaveConfig.InputTrigger = TIM_TS_ITR0;
  if (HAL_TIM_SlaveConfigSynchro(&htim8, &sSlaveConfig) != HAL_OK)
  {
    Error_Handler();
  }
  sMasterConfig.MasterOutputTrigger = TIM_TRGO_UPDATE;
  sMasterConfig.MasterOutputTrigger2 = TIM_TRGO2_RESET;
  sMasterConfig.MasterSlaveMode = TIM_MASTERSLAVEMODE_DISABLE;
  if (HAL_TIMEx_MasterConfigSynchronization(&htim8, &sMasterConfig) != HAL_OK)
  {
    Error_Handler();
  }
  sConfigOC.OCMode = TIM_OCMODE_PWM1;
  sConfigOC.Pulse = 0;
  sConfigOC.OCPolarity = TIM_OCPOLARITY_HIGH;
  sConfigOC.OCNPolarity = TIM_OCNPOLARITY_HIGH;
  sConfigOC.OCFastMode = TIM_OCFAST_DISABLE;
  sConfigOC.OCIdleState = TIM_OCIDLESTATE_RESET;
  sConfigOC.OCNIdleState = TIM_OCNIDLESTATE_RESET;
  if (HAL_TIM_PWM_ConfigChannel(&htim8, &sConfigOC, TIM_CHANNEL_1) != HAL_OK)
  {
    Error_Handler();
  }
  if (HAL_TIM_PWM_ConfigChannel(&htim8, &sConfigOC, TIM_CHANNEL_2) != HAL_OK)
  {
    Error_Handler();
  }
  if (HAL_TIM_PWM_ConfigChannel(&htim8, &sConfigOC, TIM_CHANNEL_3) != HAL_OK)
  {
    Error_Handler();
  }
  sBreakDeadTimeConfig.OffStateRunMode = TIM_OSSR_DISABLE;
  sBreakDeadTimeConfig.OffStateIDLEMode = TIM_OSSI_DISABLE;
  sBreakDeadTimeConfig.LockLevel = TIM_LOCKLEVEL_OFF;
  sBreakDeadTimeConfig.DeadTime = 170;
  sBreakDeadTimeConfig.BreakState = TIM_BREAK_DISABLE;
  sBreakDeadTimeConfig.BreakPolarity = TIM_BREAKPOLARITY_HIGH;
  sBreakDeadTimeConfig.BreakFilter = 0;
  sBreakDeadTimeConfig.BreakAFMode = TIM_BREAK_AFMODE_INPUT;
  sBreakDeadTimeConfig.Break2State = TIM_BREAK2_DISABLE;
  sBreakDeadTimeConfig.Break2Polarity = TIM_BREAK2POLARITY_HIGH;
  sBreakDeadTimeConfig.Break2Filter = 0;
  sBreakDeadTimeConfig.Break2AFMode = TIM_BREAK_AFMODE_INPUT;
  sBreakDeadTimeConfig.AutomaticOutput = TIM_AUTOMATICOUTPUT_DISABLE;
  if (HAL_TIMEx_ConfigBreakDeadTime(&htim8, &sBreakDeadTimeConfig) != HAL_OK)
  {
    Error_Handler();
  }
  HAL_TIM_MspPostInit(&htim8);

}

static void MX_USART2_UART_Init(void)
{

  huart2.Instance = USART2;
  huart2.Init.BaudRate = 115200;
  huart2.Init.WordLength = UART_WORDLENGTH_8B;
  huart2.Init.StopBits = UART_STOPBITS_1;
  huart2.Init.Parity = UART_PARITY_NONE;
  huart2.Init.Mode = UART_MODE_TX_RX;
  huart2.Init.HwFlowCtl = UART_HWCONTROL_NONE;
  huart2.Init.OverSampling = UART_OVERSAMPLING_16;
  huart2.Init.OneBitSampling = UART_ONE_BIT_SAMPLE_DISABLE;
  huart2.Init.ClockPrescaler = UART_PRESCALER_DIV1;
  huart2.AdvancedInit.AdvFeatureInit = UART_ADVFEATURE_NO_INIT;
  if (HAL_UART_Init(&huart2) != HAL_OK)
  {
    Error_Handler();
  }
  if (HAL_UARTEx_SetTxFifoThreshold(&huart2, UART_TXFIFO_THRESHOLD_1_8) != HAL_OK)
  {
    Error_Handler();
  }
  if (HAL_UARTEx_SetRxFifoThreshold(&huart2, UART_RXFIFO_THRESHOLD_1_8) != HAL_OK)
  {
    Error_Handler();
  }
  if (HAL_UARTEx_DisableFifoMode(&huart2) != HAL_OK)
  {
    Error_Handler();
  }

}

static void MX_DMA_Init(void)
{

  /* DMA controller clock enable */
  __HAL_RCC_DMAMUX1_CLK_ENABLE();
  __HAL_RCC_DMA1_CLK_ENABLE();

  /* DMA interrupt init */
  /* DMA1_Channel2_IRQn interrupt configuration */
  HAL_NVIC_SetPriority(DMA1_Channel2_IRQn, 0, 0);
  HAL_NVIC_EnableIRQ(DMA1_Channel2_IRQn);

}

static void MX_GPIO_Init(void)
{
  GPIO_InitTypeDef GPIO_InitStruct = {0};

  /* GPIO Ports Clock Enable */
  __HAL_RCC_GPIOE_CLK_ENABLE();
  __HAL_RCC_GPIOC_CLK_ENABLE();
  __HAL_RCC_GPIOF_CLK_ENABLE();
  __HAL_RCC_GPIOA_CLK_ENABLE();
  __HAL_RCC_GPIOB_CLK_ENABLE();
  __HAL_RCC_GPIOD_CLK_ENABLE();
  __HAL_RCC_GPIOG_CLK_ENABLE();

  /*Configure GPIO pin Output Level */
  HAL_GPIO_WritePin(GPIOE, GPIO_PIN_3, GPIO_PIN_RESET);

  /*Configure GPIO pin Output Level */
  HAL_GPIO_WritePin(GPIOF, GPIO_PIN_7|GPIO_PIN_8|GPIO_PIN_9|GPIO_PIN_10, GPIO_PIN_RESET);

  /*Configure GPIO pin Output Level */
  HAL_GPIO_WritePin(GPIOD, GPIO_PIN_13, GPIO_PIN_RESET);

  /*Configure GPIO pin Output Level */
  HAL_GPIO_WritePin(GPIOG, GPIO_PIN_5, GPIO_PIN_RESET);

  /*Configure GPIO pin : PE3 */
  GPIO_InitStruct.Pin = GPIO_PIN_3;
  GPIO_InitStruct.Mode = GPIO_MODE_OUTPUT_PP;
  GPIO_InitStruct.Pull = GPIO_NOPULL;
  GPIO_InitStruct.Speed = GPIO_SPEED_FREQ_LOW;
  HAL_GPIO_Init(GPIOE, &GPIO_InitStruct);

  /*Configure GPIO pins : PF7 PF8 PF9 PF10 */
  GPIO_InitStruct.Pin = GPIO_PIN_7|GPIO_PIN_8|GPIO_PIN_9|GPIO_PIN_10;
  GPIO_InitStruct.Mode = GPIO_MODE_OUTPUT_PP;
  GPIO_InitStruct.Pull = GPIO_NOPULL;
  GPIO_InitStruct.Speed = GPIO_SPEED_FREQ_LOW;
  HAL_GPIO_Init(GPIOF, &GPIO_InitStruct);

  /*Configure GPIO pins : PA4 PA5 */
  GPIO_InitStruct.Pin = GPIO_PIN_4|GPIO_PIN_5;
  GPIO_InitStruct.Mode = GPIO_MODE_INPUT;
  GPIO_InitStruct.Pull = GPIO_NOPULL;
  HAL_GPIO_Init(GPIOA, &GPIO_InitStruct);

  /*Configure GPIO pins : PF14 PF15 */
  GPIO_InitStruct.Pin = GPIO_PIN_14|GPIO_PIN_15;
  GPIO_InitStruct.Mode = GPIO_MODE_INPUT;
  GPIO_InitStruct.Pull = GPIO_NOPULL;
  HAL_GPIO_Init(GPIOF, &GPIO_InitStruct);

  /*Configure GPIO pins : PB12 PB13 PB14 */
  GPIO_InitStruct.Pin = GPIO_PIN_12|GPIO_PIN_13|GPIO_PIN_14;
  GPIO_InitStruct.Mode = GPIO_MODE_INPUT;
  GPIO_InitStruct.Pull = GPIO_NOPULL;
  HAL_GPIO_Init(GPIOB, &GPIO_InitStruct);

  /*Configure GPIO pins : PD10 PD1 */
  GPIO_InitStruct.Pin = GPIO_PIN_10|GPIO_PIN_1;
  GPIO_InitStruct.Mode = GPIO_MODE_INPUT;
  GPIO_InitStruct.Pull = GPIO_NOPULL;
  HAL_GPIO_Init(GPIOD, &GPIO_InitStruct);

  /*Configure GPIO pin : PD13 */
  GPIO_InitStruct.Pin = GPIO_PIN_13;
  GPIO_InitStruct.Mode = GPIO_MODE_OUTPUT_PP;
  GPIO_InitStruct.Pull = GPIO_NOPULL;
  GPIO_InitStruct.Speed = GPIO_SPEED_FREQ_LOW;
  HAL_GPIO_Init(GPIOD, &GPIO_InitStruct);

  /*Configure GPIO pin : PG5 */
  GPIO_InitStruct.Pin = GPIO_PIN_5;
  GPIO_InitStruct.Mode = GPIO_MODE_OUTPUT_PP;
  GPIO_InitStruct.Pull = GPIO_NOPULL;
  GPIO_InitStruct.Speed = GPIO_SPEED_FREQ_LOW;
  HAL_GPIO_Init(GPIOG, &GPIO_InitStruct);

}

/* USER CODE BEGIN 4 */

void Reset_Controllers(void){
	pi_id1.ui = 0; pi_id1.i1 = 0; pi_id1.Out = 0;
	pi_iq1.ui = 0; pi_iq1.i1 = 0; pi_iq1.Out = 0;
	pi_id2.ui = 0; pi_id2.i1 = 0; pi_id2.Out = 0;
	pi_id2.ui = 0; pi_id2.i1 = 0; pi_iq2.Out = 0;
	pi_id.ui  = 0; pi_id.i1 = 0; pi_id.Out = 0;
	pi_iq.ui  = 0; pi_iq.i1 = 0; pi_iq.Out = 0;
	pi_ix.ui  = 0; pi_ix.i1 = 0; pi_ix.Out = 0;
	pi_iy.ui  = 0; pi_iy.i1 = 0; pi_iy.Out = 0;

}

void PWM_start(void){

	  HAL_TIM_PWM_Start(&htim1, TIM_CHANNEL_1);
	  HAL_TIMEx_PWMN_Start(&htim1, TIM_CHANNEL_1);
	  HAL_TIM_PWM_Start(&htim1, TIM_CHANNEL_2);
	  HAL_TIMEx_PWMN_Start(&htim1, TIM_CHANNEL_2);
	  HAL_TIM_PWM_Start(&htim1, TIM_CHANNEL_3);
	  HAL_TIMEx_PWMN_Start(&htim1, TIM_CHANNEL_3);

	  HAL_TIM_PWM_Start(&htim8, TIM_CHANNEL_1);
	  HAL_TIMEx_PWMN_Start(&htim8, TIM_CHANNEL_1);
	  HAL_TIM_PWM_Start(&htim8, TIM_CHANNEL_2);
	  HAL_TIMEx_PWMN_Start(&htim8, TIM_CHANNEL_2);
	  HAL_TIM_PWM_Start(&htim8, TIM_CHANNEL_3);
	  HAL_TIMEx_PWMN_Start(&htim8, TIM_CHANNEL_3);
}

void PWM_stop(void){
	  HAL_TIM_PWM_Stop(&htim1, TIM_CHANNEL_1);
	  HAL_TIMEx_PWMN_Stop(&htim1, TIM_CHANNEL_1);
	  HAL_TIM_PWM_Stop(&htim1, TIM_CHANNEL_2);
	  HAL_TIMEx_PWMN_Stop(&htim1, TIM_CHANNEL_2);
	  HAL_TIM_PWM_Stop(&htim1, TIM_CHANNEL_3);
	  HAL_TIMEx_PWMN_Stop(&htim1, TIM_CHANNEL_3);

	  HAL_TIM_PWM_Stop(&htim8, TIM_CHANNEL_1);
	  HAL_TIMEx_PWMN_Stop(&htim8, TIM_CHANNEL_1);
	  HAL_TIM_PWM_Stop(&htim8, TIM_CHANNEL_2);
	  HAL_TIMEx_PWMN_Stop(&htim8, TIM_CHANNEL_2);
	  HAL_TIM_PWM_Stop(&htim8, TIM_CHANNEL_3);
	  HAL_TIMEx_PWMN_Stop(&htim8, TIM_CHANNEL_3);
}

void PrintScreen(void)
{
//    msg = "\033[2J\0";
	if(clear_screen)
	{
		strcpy((char*)msg,"\033[2J\0");
		HAL_UART_Transmit(&huart2,msg,strlen((char*)msg),HAL_MAX_DELAY);
		clear_screen=0;
	}

	strcpy((char*)msg,"\033[2;20HABB USRC SPACER Project PFC\0");
    HAL_UART_Transmit(&huart2,msg,strlen((char*)msg),HAL_MAX_DELAY);

// Line 2
    strcpy((char*)msg,"\033[5;1HFrequency=\0");
    HAL_UART_Transmit(&huart2,msg,strlen((char*)msg),HAL_MAX_DELAY);
	sprintf(msg,"%f    ",freq_pu);
	HAL_UART_Transmit(&huart2, (uint8_t*)msg, strlen(msg), HAL_MAX_DELAY);
//
//    strcpy((char*)msg,"\033[5;25HIL ADC=\0");
//    HAL_UART_Transmit(&huart2,msg,strlen((char*)msg),HAL_MAX_DELAY);
//	sprintf(msg,"%u    ",IL_INT);
//	HAL_UART_Transmit(&huart2, (uint8_t*)msg, strlen(msg), HAL_MAX_DELAY);

//    strcpy((char*)msg,"\033[5;50HIL=\0");
//    HAL_UART_Transmit(&huart2,msg,strlen((char*)msg),HAL_MAX_DELAY);
//	sprintf(msg,"%f    ",IL);
//	HAL_UART_Transmit(&huart2, (uint8_t*)msg, strlen(msg), HAL_MAX_DELAY);

	//Line 3
//    strcpy((char*)msg,"\033[7;1HIsRelayOn=\0");
//    HAL_UART_Transmit(&huart2,msg,strlen((char*)msg),HAL_MAX_DELAY);
//	//sprintf(msg,"%hu\r\n",Vdc_INT);
//	sprintf(msg,"%f    ",IsRelayOn);
//	HAL_UART_Transmit(&huart2, (uint8_t*)msg, strlen(msg), HAL_MAX_DELAY);

//    strcpy((char*)msg,"\033[7;25HPFC_duty=\0");
//    HAL_UART_Transmit(&huart2,msg,strlen((char*)msg),HAL_MAX_DELAY);
//	sprintf(msg,"%f    ",duty);
//	//snprintf(num,4,"%u",Vac);
//	HAL_UART_Transmit(&huart2, (uint8_t*)msg, strlen(msg), HAL_MAX_DELAY);

//    strcpy((char*)msg,"\033[7;50HonOff status=\0");
//    HAL_UART_Transmit(&huart2,msg,strlen((char*)msg),HAL_MAX_DELAY);
//	sprintf(msg,"%u    ",Read_OnOff_Control);
//	//snprintf(num,4,"%u",Vac);
//	HAL_UART_Transmit(&huart2, (uint8_t*)msg, strlen(msg), HAL_MAX_DELAY);

	//line 4
    strcpy((char*)msg,"\033[9;1HEARTH_Fault=\0");
    HAL_UART_Transmit(&huart2,msg,strlen((char*)msg),HAL_MAX_DELAY);
	//sprintf(msg,"%hu\r\n",Vdc_INT);
	sprintf(msg,"%u    ",Read_EARTH_Fault);
	HAL_UART_Transmit(&huart2, (uint8_t*)msg, strlen(msg), HAL_MAX_DELAY);

    strcpy((char*)msg,"\033[9;25HOC_Fault=\0");
    HAL_UART_Transmit(&huart2,msg,strlen((char*)msg),HAL_MAX_DELAY);
	sprintf(msg,"%u    ",Read_OC_Fault);
	//snprintf(num,4,"%u",Vac);
	HAL_UART_Transmit(&huart2, (uint8_t*)msg, strlen(msg), HAL_MAX_DELAY);

    strcpy((char*)msg,"\033[9;50HSC_Fault=\0");
    HAL_UART_Transmit(&huart2,msg,strlen((char*)msg),HAL_MAX_DELAY);
	sprintf(msg,"%u    ",Read_SC_Fault);
	//snprintf(num,4,"%u",Vac);
	HAL_UART_Transmit(&huart2, (uint8_t*)msg, strlen(msg), HAL_MAX_DELAY);

	//line 5
//    strcpy((char*)msg,"\033[11;1HIL_ref=\0");
//    HAL_UART_Transmit(&huart2,msg,strlen((char*)msg),HAL_MAX_DELAY);
//	//sprintf(msg,"%hu\r\n",Vdc_INT);
//	sprintf(msg,"%f    ",IL_ref);
//	HAL_UART_Transmit(&huart2, (uint8_t*)msg, strlen(msg), HAL_MAX_DELAY);
//
//    strcpy((char*)msg,"\033[11;25HVc=\0");
//    HAL_UART_Transmit(&huart2,msg,strlen((char*)msg),HAL_MAX_DELAY);
//	sprintf(msg,"%f    ",Vary_Vc);
//	HAL_UART_Transmit(&huart2, (uint8_t*)msg, strlen(msg), HAL_MAX_DELAY);
//
//    strcpy((char*)msg,"\033[11;50HVac=\0");
//    HAL_UART_Transmit(&huart2,msg,strlen((char*)msg),HAL_MAX_DELAY);
//	sprintf(msg,"%f    ",Vac);
//	HAL_UART_Transmit(&huart2, (uint8_t*)msg, strlen(msg), HAL_MAX_DELAY);
//
//	//line 6
//    strcpy((char*)msg,"\033[13;1HDmndCurr=\0");
//    HAL_UART_Transmit(&huart2,msg,strlen((char*)msg),HAL_MAX_DELAY);
//	sprintf(msg,"%f    ",DemandCurrent);
//	HAL_UART_Transmit(&huart2, (uint8_t*)msg, strlen(msg), HAL_MAX_DELAY);
//
//    strcpy((char*)msg,"\033[13;25HPFC I-protection=\0");
//    HAL_UART_Transmit(&huart2,msg,strlen((char*)msg),HAL_MAX_DELAY);
//	sprintf(msg,"%u    ",CurrProtection_ON);
//	HAL_UART_Transmit(&huart2, (uint8_t*)msg, strlen(msg), HAL_MAX_DELAY);
//
//    strcpy((char*)msg,"\033[13;50HVdc_target=\0");
//    HAL_UART_Transmit(&huart2,msg,strlen((char*)msg),HAL_MAX_DELAY);
//	sprintf(msg,"%f    ",VdcTarget);
//	HAL_UART_Transmit(&huart2, (uint8_t*)msg, strlen(msg), HAL_MAX_DELAY);
//
//	//Line 7
//    strcpy((char*)msg,"\033[15;1HPFC V-protection=\0");
//    HAL_UART_Transmit(&huart2,msg,strlen((char*)msg),HAL_MAX_DELAY);
//	sprintf(msg,"%u    ",VolProtection_ON);
//	HAL_UART_Transmit(&huart2, (uint8_t*)msg, strlen(msg), HAL_MAX_DELAY);
//
//    strcpy((char*)msg,"\033[15;25HDmdCurrMax=\0");
//    HAL_UART_Transmit(&huart2,msg,strlen((char*)msg),HAL_MAX_DELAY);
//	sprintf(msg,"%f    ",DemandCurrentMAX);
//	HAL_UART_Transmit(&huart2, (uint8_t*)msg, strlen(msg), HAL_MAX_DELAY);

}

void printDataLog(int16_t *DataBuffer1, int16_t *DataBuffer2, int16_t *DataBuffer3, int16_t *DataBuffer4, uint16_t dataBufferLength, uint16_t *start)
{
    //unsigned char *u;
    int i=0;

    // Clear screen first
	strcpy((char*)msg,"\033[2J\033[1;1H\0");
	HAL_UART_Transmit(&huart2,msg,strlen((char*)msg),HAL_MAX_DELAY);

    for(i=0;i<dataBufferLength;i++)
    {

     	sprintf(msg,"%f\t",fBuff1[i]);
     	HAL_UART_Transmit(&huart2, (uint8_t*)msg, strlen(msg), 10);

     	sprintf(msg,"%f\t",fBuff2[i]);
     	HAL_UART_Transmit(&huart2, (uint8_t*)msg, strlen(msg), 10);

     	sprintf(msg,"%f\t",fBuff3[i]);
     	HAL_UART_Transmit(&huart2, (uint8_t*)msg, strlen(msg), 10);

     	sprintf(msg,"%f\r\n",fBuff4[i]);
     	HAL_UART_Transmit(&huart2, (uint8_t*)msg, strlen(msg), 10);

    }

	strcpy((char*)msg,"\033[2J\0");
	HAL_UART_Transmit(&huart2,msg,strlen((char*)msg),HAL_MAX_DELAY);

    *start=0;
    clear_screen=1;
    trigger=0;
    trigger_float=0;

}

void HAL_ADCEx_InjectedConvCpltCallback(ADC_HandleTypeDef* hadc)
{
#if (MODE == MODE_1)
 {
//	HAL_GPIO_WritePin(GPIOF, GPIO_PIN_8, GPIO_PIN_SET);
    Inj_A1 = HAL_ADCEx_InjectedGetValue(&hadc2, ADC_INJECTED_RANK_1); // PC0
    Inj_B1 = HAL_ADCEx_InjectedGetValue(&hadc2, ADC_INJECTED_RANK_2); // PA6
    Inj_A2 = HAL_ADCEx_InjectedGetValue(&hadc2, ADC_INJECTED_RANK_3); // PC1
    Inj_B2 = HAL_ADCEx_InjectedGetValue(&hadc2, ADC_INJECTED_RANK_4); // PA7

    //1.5V is 0 value for ADC --> 1861, not 1.65V
	A1 = ((Inj_A1+66)*Three3VBy4095 + V_Offset)/Slope_A1 ;
	B1 = ((Inj_B1+66)*Three3VBy4095 + V_Offset)/Slope_B1;
	C1 = -(A1+B1);

	A2 = ((Inj_A2+66)*Three3VBy4095 + V_Offset)/Slope_A2 ;
	B2 = ((Inj_B2+66)*Three3VBy4095 + V_Offset)/Slope_B2;
	C2 = -(A2+B2);

	if (Activate == 1)
	{

		rc1.TargetValue = freq_pu;
		RC_MACRO(rc1);

		rg1.Freq = rc1.SetpointValue;
		RG_MACRO(rg1);

		// define inputs for inverse park transform
		Angle1  = rg1.Out*2*PI ;
		Angle2  = fmod((Angle1 - phase_shift),TwoPI);

		vhz1.Freq = rc1.SetpointValue;
		VHZ_PROF_MACRO(vhz1);

		Vq = 0;
		Vd = vhz1.VoltOut;

		ipark1.Sine   = sin(Angle1);
		ipark1.Cosine = cos(Angle1);
		ipark2.Sine   = sin(Angle2);
		ipark2.Cosine = cos(Angle2);

		ipark1.Ds = Vd;
		ipark1.Qs = Vq;
		ipark2.Ds = Vd;
		ipark2.Qs = Vq;

		IPARK_MACRO(ipark1);
		IPARK_MACRO(ipark2);

//		clarke1.As = -A1*INV_IBASE;
//		clarke1.Bs = -B1*INV_IBASE;
//		CLARKE_MACRO(clarke1);

//		volt1.DcBusVolt = 1;
//		volt1.MfuncV1 = svgen1.Ta;
//		volt1.MfuncV2 = svgen1.Tb;
//		volt1.MfuncV3 = svgen1.Tc;
//		PHASEVOLT_MACRO(volt1);
//
//		flux1.UDsS = volt1.Valpha;
//		flux1.UQsS = volt1.Vbeta;
//		flux1.IDsS = clarke1.Alpha;
//		flux1.IQsS = clarke1.Beta;
//		FLUX_OBS_MACRO(flux1);
//
//		speed1.IDsS = clarke1.Alpha;
//		speed1.IQsS = clarke1.Beta;
//		speed1.PsiDrS = flux1.PsiDrS;
//		speed1.PsiQrS = flux1.PsiQrS;
//		speed1.ThetaFlux = flux1.ThetaFlux*Oneby2PI;
//		SPEEDEST_MACRO(speed1);

		// define inputs for Space vector Generation
		svgen1.Ualpha = ipark1.Alpha;
		svgen1.Ubeta  = ipark1.Beta;
		svgen2.Ualpha = ipark2.Alpha;
		svgen2.Ubeta  = ipark2.Beta;

		SVGENDQ_MACRO(svgen1);
		SVGENDQ_MACRO(svgen2);

	}
//	HAL_GPIO_WritePin(GPIOF, GPIO_PIN_8, GPIO_PIN_RESET);
 }
#endif

#if (MODE == MODE_2)
 {

 //	HAL_GPIO_WritePin(GPIOF, GPIO_PIN_8, GPIO_PIN_SET);
	Inj_A1 = HAL_ADCEx_InjectedGetValue(&hadc2, ADC_INJECTED_RANK_1); // PC0
	Inj_B1 = HAL_ADCEx_InjectedGetValue(&hadc2, ADC_INJECTED_RANK_2); // PA6
	Inj_A2 = HAL_ADCEx_InjectedGetValue(&hadc2, ADC_INJECTED_RANK_3); // PC1
	Inj_B2 = HAL_ADCEx_InjectedGetValue(&hadc2, ADC_INJECTED_RANK_4); // PA7

	 //1.5V is 0 value for ADC --> 1861, not 1.65V
	A1 = ((Inj_A1+66)*Three3VBy4095 + V_Offset)/Slope_A1 ;
	B1 = ((Inj_B1+66)*Three3VBy4095 + V_Offset)/Slope_B1;
	C1 = -(A1+B1);

	A2 = ((Inj_A2+66)*Three3VBy4095 + V_Offset)/Slope_A2 ;
	B2 = ((Inj_B2+66)*Three3VBy4095 + V_Offset)/Slope_B2;
	C2 = -(A2+B2);

	if (Enable == 1)
	{
		rc1.TargetValue = freq_pu;
		RC_MACRO(rc1);

		rg1.Freq = rc1.SetpointValue;
		RG_MACRO(rg1);

		// define inputs for inverse park transform
		Angle  = rg1.Out*TwoPI ;
		Angle6 = fmod(Angle,TwoPI);

		vhz1.Freq = rc1.SetpointValue;
		VHZ_PROF_MACRO(vhz1);

		Valpha = vhz1.VoltOut*cos(Angle);
		Vbeta = vhz1.VoltOut*sin(Angle);

		// Angle for XY subspace transformation
		ipark2.Sine   = sin(Angle);
		park2.Sine = ipark2.Sine;

		ipark2.Cosine = cos(Angle);
		park2.Cosine = ipark2.Cosine;

		// VSD Transform for current
		vsd.As1 = -A1*INV_IBASE;
		vsd.Bs1 = -B1*INV_IBASE;
		vsd.Cs1 = -C1*INV_IBASE;
		vsd.As2 = -A2*INV_IBASE;
		vsd.Bs2 = -B2*INV_IBASE;
		vsd.Cs2 = -C2*INV_IBASE;
		VSD_MACRO(vsd);

		// Park Transform
        park2.Alpha = vsd.X;
        park2.Beta = vsd.Y;
        PARK_MACRO(park2);

        // PI Controllers - XY_frame
		pi_ix.Ref = 0;
		pi_ix.Fbk = park2.Qs;
		PI_MACRO(pi_ix);

		pi_iy.Ref = 0;
		pi_iy.Fbk = park2.Ds;
		PI_MACRO(pi_iy);

		//Inverse Park Transform
		ipark2.Ds = pi_ix.Out ;
		ipark2.Qs = pi_iy.Out ;
		IPARK_MACRO(ipark2);

        // Inverse VSD Transform
		ivsd.Alpha = Valpha;
		ivsd.Beta = Vbeta;

		if (Activate == 1)
		{
			ivsd.X = ipark2.Alpha;
			ivsd.Y = ipark2.Beta;
		}
		else
		{
			ivsd.X = 0;
			ivsd.Y = 0;
		}
		IVSD_MACRO(ivsd);

		volt1.DcBusVolt = 1;
		volt1.MfuncV1 = ivsd.As1;
		volt1.MfuncV2 = ivsd.Bs1;
		volt1.MfuncV3 = ivsd.Cs1;
		PHASEVOLT_MACRO(volt1);

		flux1.UDsS = volt1.Valpha;
		flux1.UQsS = volt1.Vbeta;
		flux1.IDsS = vsd.Alpha;
		flux1.IQsS = vsd.Beta;
		FLUX_OBS_MACRO(flux1);

		speed1.IDsS = vsd.Alpha;
		speed1.IQsS = vsd.Beta;
		speed1.PsiDrS = flux1.PsiDrS;
		speed1.PsiQrS = flux1.PsiQrS;
		speed1.ThetaFlux = flux1.ThetaFlux*Oneby2PI;
		SPEEDEST_MACRO(speed1);

	}
 }
#endif

// Dual Vector control, Double SVM
#if (MODE == MODE_3)
 {
	Inj_A1 = HAL_ADCEx_InjectedGetValue(&hadc2, ADC_INJECTED_RANK_1);
	Inj_B1 = HAL_ADCEx_InjectedGetValue(&hadc2, ADC_INJECTED_RANK_2);
	Inj_A2 = HAL_ADCEx_InjectedGetValue(&hadc2, ADC_INJECTED_RANK_3);
	Inj_B2 = HAL_ADCEx_InjectedGetValue(&hadc2, ADC_INJECTED_RANK_4);

	A1 = Inj_A1 * SlopeA1 + A1_Intercept;
	B1 = Inj_B1 * SlopeA1 + A1_Intercept;
	C1 = -(A1+B1);

	A2 = Inj_A2 * SlopeA1 + A1_Intercept;
	B2 = Inj_B2 * SlopeA1 + A1_Intercept;
	C2 = -(A2+B2);

    if (ClosedCurrent == 1)
    {

    	rc1.TargetValue = freq_pu;
		RC_MACRO(rc1);

		rg1.Freq = rc1.SetpointValue;
		RG_MACRO(rg1);

		// define angle inputs for synchronous transformation
		if (ClosedSpeed == 0)
		{
			Angle1 = rg1.Out*TwoPI ;
		}
		else Angle1 = flux1.ThetaFlux ;
		Angle2 = fmod((Angle1 - phase_shift),TwoPI);

		ipark1.Sine   = sin(Angle1);
		park1.Sine = ipark1.Sine;

		ipark1.Cosine = cos(Angle1);
		park1.Cosine = ipark1.Cosine;

		ipark2.Sine   = sin(Angle2);
	    park2.Sine = ipark2.Sine;

		ipark2.Cosine = cos(Angle2);
		park2.Cosine = ipark2.Cosine;

		clarke1.As = -A1*INV_IBASE;
		clarke1.Bs = -B1*INV_IBASE;
		CLARKE_MACRO(clarke1);

		clarke2.As = -A2*INV_IBASE;
		clarke2.Bs = -B2*INV_IBASE;
		CLARKE_MACRO(clarke2);

		park1.Alpha = clarke1.Alpha;
		park1.Beta = clarke1.Beta;
		PARK_MACRO(park1);

		park2.Alpha = clarke2.Alpha;
		park2.Beta = clarke2.Beta;
		PARK_MACRO(park2);

		if (SpeedLoopCount == SpeedLoopPrescaler)
		{
			pi_spd.Ref = rc1.SetpointValue;
			pi_spd.Fbk = speed1.WrHat;
			PI_MACRO(pi_spd);
			SpeedLoopCount = 1;
		}
		else SpeedLoopCount++;

		if (ClosedSpeed == 0)
		{
			pi_iq1.Ref = 0;
			pi_iq2.Ref = 0;
			pi_spd.ui = 0;
			pi_spd.i1 = 0;
		}
		else
		{	pi_iq1.Ref = pi_spd.Out;
			pi_iq2.Ref = pi_spd.Out;
		}

		// PI Controller - First Winding Set
		pi_iq1.Fbk = park1.Qs;
		PI_MACRO(pi_iq1);

		pi_id1.Ref = IdRef;
		pi_id1.Fbk = park1.Ds;
		PI_MACRO(pi_id1);

		// PI Controller - Second Winding Set
		pi_iq2.Fbk = park2.Qs;
		PI_MACRO(pi_iq2);

		pi_id2.Ref = IdRef;
		pi_id2.Fbk = park2.Ds;
		PI_MACRO(pi_id2);

		// Inverse Park Transforms
		ipark1.Ds = pi_id1.Out;
		ipark1.Qs = pi_iq1.Out;
		IPARK_MACRO(ipark1);

		ipark2.Ds = pi_id2.Out;
		ipark2.Qs = pi_iq2.Out;
		IPARK_MACRO(ipark2);

		// Voltage reconstruction and speed estimation
		volt1.DcBusVolt = 1;
		volt1.MfuncV1 = svgen1.Ta;
		volt1.MfuncV2 = svgen1.Tb;
		volt1.MfuncV3 = svgen1.Tc;
		PHASEVOLT_MACRO(volt1);

		flux1.UDsS = volt1.Valpha;
		flux1.UQsS = volt1.Vbeta;
		flux1.IDsS = clarke1.Alpha;
		flux1.IQsS = clarke1.Beta;
		FLUX_OBS_MACRO(flux1);

		speed1.IDsS = clarke1.Alpha;
		speed1.IQsS = clarke1.Beta;
		speed1.PsiDrS = flux1.PsiDrS;
		speed1.PsiQrS = flux1.PsiQrS;
		speed1.ThetaFlux = flux1.ThetaFlux*Oneby2PI;
		SPEEDEST_MACRO(speed1);

		// define inputs for Space vector Generation
		svgen1.Ualpha = ipark1.Alpha;
		svgen1.Ubeta  = ipark1.Beta;
		SVGENDQ_MACRO(svgen1);

		svgen2.Ualpha = ipark2.Alpha;
		svgen2.Ubeta  = ipark2.Beta;
		SVGENDQ_MACRO(svgen2);

    }

  }
#endif

#if (MODE == MODE_4) // VSD Controller, Double PWM
{
//	HAL_GPIO_WritePin(GPIOF, GPIO_PIN_8, GPIO_PIN_SET);
	 Inj_A1 = HAL_ADCEx_InjectedGetValue(&hadc2, ADC_INJECTED_RANK_1); // PC0
	 Inj_B1 = HAL_ADCEx_InjectedGetValue(&hadc2, ADC_INJECTED_RANK_2); // PA6
	 Inj_A2 = HAL_ADCEx_InjectedGetValue(&hadc2, ADC_INJECTED_RANK_3); // PC1
	 Inj_B2 = HAL_ADCEx_InjectedGetValue(&hadc2, ADC_INJECTED_RANK_4); // PA7

	 //1.5V is 0 value for ADC --> 1861, not 1.65V
	A1 = ((Inj_A1+66)*Three3VBy4095 + V_Offset)/Slope_A1 ;
	B1 = ((Inj_B1+66)*Three3VBy4095 + V_Offset)/Slope_B1;
	C1 = -(A1+B1);

	A2 = ((Inj_A2+66)*Three3VBy4095 + V_Offset)/Slope_A2 ;
	B2 = ((Inj_B2+66)*Three3VBy4095 + V_Offset)/Slope_B2;
	C2 = -(A2+B2);

	if (ClosedCurrent == 1)
	{
		rc1.TargetValue = freq_pu;
		RC_MACRO(rc1);

		rg1.Freq = rc1.SetpointValue;
		RG_MACRO(rg1);

		// define angle inputs for synchronous transformation
		if (ClosedSpeed == 0)
		{
			Angle = rg1.Out*TwoPI ;
		}
		else Angle = flux1.ThetaFlux ;

		ipark1.Sine   = sin(Angle);
		park1.Sine = ipark1.Sine;

		ipark1.Cosine = cos(Angle);
		park1.Cosine = ipark1.Cosine;

		ipark2.Sine   = sin(Angle);
		park2.Sine = ipark2.Sine;

		ipark2.Cosine = cos(Angle);
		park2.Cosine = ipark2.Cosine;

		// VSD Transform
		vsd1.As1 = -A1*INV_IBASE;
		vsd1.Bs1 = -B1*INV_IBASE;
		vsd1.Cs1 = -C1*INV_IBASE;
		vsd1.As2 = -A2*INV_IBASE;
		vsd1.Bs2 = -B2*INV_IBASE;
		vsd1.Cs2 = -C2*INV_IBASE;
		VSD_MACRO(vsd1);

		// Park Transforms
		park1.Alpha = vsd1.Alpha;
		park1.Beta = vsd1.Beta;
		PARK_MACRO(park1);

		park2.Alpha = vsd1.X;
		park2.Beta = vsd1.Y;
		PARK_MACRO(park2);

		if (SpeedLoopCount == SpeedLoopPrescaler)
		{
			pi_spd.Ref = rc1.SetpointValue;
			pi_spd.Fbk = speed1.WrHat;
			PI_MACRO(pi_spd);
			SpeedLoopCount = 1;
		}
		else SpeedLoopCount++;

		if (ClosedSpeed == 0)
		{
			pi_iq.Ref = 0;
			pi_spd.ui = 0;
			pi_spd.i1 = 0;
		}
		else
		{	pi_iq.Ref = pi_spd.Out;
		}

		// PI Controllers - DQ_frame
		pi_iq.Fbk = park1.Qs;
		PI_MACRO(pi_iq);

		pi_id.Ref = IdRef;
		pi_id.Fbk = park1.Ds;
		PI_MACRO(pi_id);

		// PI Controllers - XY_frame
		pi_ix.Ref = 0;
		pi_ix.Fbk = park2.Ds;
		PI_MACRO(pi_ix);

		pi_iy.Ref = 0;
		pi_iy.Fbk = park2.Qs;
		PI_MACRO(pi_iy);

		// Inverse Park Transforms
		ipark1.Ds = pi_id.Out;
		ipark1.Qs = pi_iq.Out;
		IPARK_MACRO(ipark1);

		ipark2.Ds = pi_ix.Out;
		ipark2.Qs = pi_iy.Out;
		IPARK_MACRO(ipark2);

		// Phase Voltage Reconstruction
		volt1.DcBusVolt = 1;
		volt1.MfuncV1 = ivsd1.As1;
		volt1.MfuncV2 = ivsd1.Bs1;
		volt1.MfuncV3 = ivsd1.Cs1;
		PHASEVOLT_MACRO(volt1);

		// Rotor Flux Observer
		flux1.UDsS = volt1.Valpha;
		flux1.UQsS = volt1.Vbeta;
		flux1.IDsS = vsd1.Alpha;
		flux1.IQsS = vsd1.Beta;
		FLUX_OBS_MACRO(flux1);

		// Speed Estimation
		speed1.IDsS = vsd1.Alpha;
		speed1.IQsS = vsd1.Beta;
		speed1.PsiDrS = flux1.PsiDrS;
		speed1.PsiQrS = flux1.PsiQrS;
		speed1.ThetaFlux = flux1.ThetaFlux*Oneby2PI;
		SPEEDEST_MACRO(speed1);

		// Inverse VSD Transform
		ivsd1.Alpha = ipark1.Alpha;
		ivsd1.Beta = ipark1.Beta;
		ivsd1.X = ipark2.Alpha;
		ivsd1.Y = ipark2.Beta;
		IVSD_MACRO(ivsd1);
        }

}

    #endif

#if (MODE == MODE_5)     //  Double I/F Control
 {
 //	HAL_GPIO_WritePin(GPIOF, GPIO_PIN_8, GPIO_PIN_SET);
	 Inj_A1 = HAL_ADCEx_InjectedGetValue(&hadc2, ADC_INJECTED_RANK_1); // PC0
	 Inj_B1 = HAL_ADCEx_InjectedGetValue(&hadc2, ADC_INJECTED_RANK_2); // PA6
	 Inj_A2 = HAL_ADCEx_InjectedGetValue(&hadc2, ADC_INJECTED_RANK_3); // PC1
	 Inj_B2 = HAL_ADCEx_InjectedGetValue(&hadc2, ADC_INJECTED_RANK_4); // PA7

	 //1.5V is 0 value for ADC --> 1861, not 1.65V
	A1 = ((Inj_A1+66)*Three3VBy4095 + V_Offset)/Slope_A1 ;
	B1 = ((Inj_B1+66)*Three3VBy4095 + V_Offset)/Slope_B1;
	C1 = -(A1+B1);

	A2 = ((Inj_A2+66)*Three3VBy4095 + V_Offset)/Slope_A2 ;
	B2 = ((Inj_B2+66)*Three3VBy4095 + V_Offset)/Slope_B2;
	C2 = -(A2+B2);

    if (Activate == 1)
    {

    	rc1.TargetValue = freq_pu;
		RC_MACRO(rc1);

		rg1.Freq = rc1.SetpointValue;
		RG_MACRO(rg1);

		Angle1 = rg1.Out*TwoPI ;
		Angle2 = fmod((Angle1 - phase_shift),TwoPI);

		ipark1.Sine   = sin(Angle1);
		park1.Sine = ipark1.Sine;

		ipark1.Cosine = cos(Angle1);
		park1.Cosine = ipark1.Cosine;

		ipark2.Sine   = sin(Angle2);
	    park2.Sine = ipark2.Sine;

		ipark2.Cosine = cos(Angle2);
		park2.Cosine = ipark2.Cosine;

		clarke1.As = -A1*INV_IBASE;
		clarke1.Bs = -B1*INV_IBASE;
		CLARKE_MACRO(clarke1);

		clarke2.As = -A2*INV_IBASE;
		clarke2.Bs = -B2*INV_IBASE;
		CLARKE_MACRO(clarke2);

		park1.Alpha = clarke1.Alpha;
		park1.Beta = clarke1.Beta;
		PARK_MACRO(park1);

		park2.Alpha = clarke2.Alpha;
		park2.Beta = clarke2.Beta;
		PARK_MACRO(park2);

		// PI Controller - First Winding Set
		pi_iq1.Ref = 0;
		pi_iq1.Fbk = park1.Qs;
		PI_MACRO(pi_iq1);

		pi_id1.Ref = IdRef;
		pi_id1.Fbk = park1.Ds;
		PI_MACRO(pi_id1);

		// PI Controller - Second Winding Set
		pi_iq2.Ref = 0;
		pi_iq2.Fbk = park2.Qs;
		PI_MACRO(pi_iq2);

		pi_id2.Ref = IdRef;
		pi_id2.Fbk = park2.Ds;
		PI_MACRO(pi_id2);

		// Inverse Park Transforms
		ipark1.Ds = pi_id1.Out;
		ipark1.Qs = pi_iq1.Out;
		IPARK_MACRO(ipark1);

		ipark2.Ds = pi_id2.Out;
		ipark2.Qs = pi_iq2.Out;
		IPARK_MACRO(ipark2);

		// define inputs for Space vector Generation
		svgen1.Ualpha = ipark1.Alpha;
		svgen1.Ubeta  = ipark1.Beta;
		SVGENDQ_MACRO(svgen1);

		svgen2.Ualpha = ipark2.Alpha;
		svgen2.Ubeta  = ipark2.Beta;
		SVGENDQ_MACRO(svgen2);

    }

  }
#endif

#if (MODE == MODE_6) // VSD I/F Controller, Double PWM
{
//	HAL_GPIO_WritePin(GPIOF, GPIO_PIN_8, GPIO_PIN_SET);
	Inj_A1 = HAL_ADCEx_InjectedGetValue(&hadc2, ADC_INJECTED_RANK_1); // PC0
	Inj_B1 = HAL_ADCEx_InjectedGetValue(&hadc2, ADC_INJECTED_RANK_2); // PA6
	Inj_A2 = HAL_ADCEx_InjectedGetValue(&hadc2, ADC_INJECTED_RANK_3); // PC1
	Inj_B2 = HAL_ADCEx_InjectedGetValue(&hadc2, ADC_INJECTED_RANK_4); // PA7

	 //1.5V is 0 value for ADC --> 1861, not 1.65V
	A1 = ((Inj_A1+66)*Three3VBy4095 + V_Offset)/Slope_A1 ;
	B1 = ((Inj_B1+66)*Three3VBy4095 + V_Offset)/Slope_B1;
	C1 = -(A1+B1);

	A2 = ((Inj_A2+66)*Three3VBy4095 + V_Offset)/Slope_A2 ;
	B2 = ((Inj_B2+66)*Three3VBy4095 + V_Offset)/Slope_B2;
	C2 = -(A2+B2);

	if (ClosedCurrent == 1)
	{
		rc1.TargetValue = freq_pu;
		RC_MACRO(rc1);

		rg1.Freq = rc1.SetpointValue;
		RG_MACRO(rg1);

		Angle = rg1.Out*TwoPI ;

		ipark1.Sine   = sin(Angle);
		park1.Sine = ipark1.Sine;

		ipark1.Cosine = cos(Angle);
		park1.Cosine = ipark1.Cosine;

		ipark2.Sine   = sin(Angle);
		park2.Sine = ipark2.Sine;

		ipark2.Cosine = cos(Angle);
		park2.Cosine = ipark2.Cosine;

		// VSD Transform
		vsd1.As1 = -A1*INV_IBASE;
		vsd1.Bs1 = -B1*INV_IBASE;
		vsd1.Cs1 = -C1*INV_IBASE;
		vsd1.As2 = -A2*INV_IBASE;
		vsd1.Bs2 = -B2*INV_IBASE;
		vsd1.Cs2 = -C2*INV_IBASE;
		VSD_MACRO(vsd1);

		// Park Transforms
		park1.Alpha = vsd1.Alpha;
		park1.Beta = vsd1.Beta;
		PARK_MACRO(park1);

		park2.Alpha = vsd1.X;
		park2.Beta = vsd1.Y;
		PARK_MACRO(park2);

		// PI Controllers - DQ_frame
	    pi_iq.Ref = 0;
		pi_iq.Fbk = park1.Qs;
		PI_MACRO(pi_iq);

		pi_id.Ref = IdRef;
		pi_id.Fbk = park1.Ds;
		PI_MACRO(pi_id);

		// PI Controllers - XY_frame
		pi_ix.Ref = 0;
		pi_ix.Fbk = park2.Ds;
		PI_MACRO(pi_ix);

		pi_iy.Ref = 0;
		pi_iy.Fbk = park2.Qs;
		PI_MACRO(pi_iy);

		// Inverse Park Transforms
		ipark1.Ds = pi_id.Out;
		ipark1.Qs = pi_iq.Out;
		IPARK_MACRO(ipark1);

		ipark2.Ds = pi_ix.Out;
		ipark2.Qs = pi_iy.Out;
		IPARK_MACRO(ipark2);

		// Inverse VSD Transform
		ivsd1.Alpha = ipark1.Alpha;
		ivsd1.Beta = ipark1.Beta;
		ivsd1.X = ipark2.Alpha;
		ivsd1.Y = ipark2.Beta;
		IVSD_MACRO(ivsd1);
        }

}

    #endif

	 if( dLogFloat.count == FBUFF_SIZE-1 )
		{
			dLogFloat.status=0;
			dLogFloat.count=0;
			print_log=1;
		}
		DATA_LOG_4CH_FLOAT_run(&dLogFloat);

}

void HAL_TIM_PeriodElapsedCallback(TIM_HandleTypeDef *htim)
{

	if (htim == &htim4)                     // PFC ISR
	{
//************************** SC & and Earth Protection for Motor ************************************
	  		  Read_SC_Fault = HAL_GPIO_ReadPin(GPIOF, GPIO_PIN_14)    ;
	  		  Read_EARTH_Fault = HAL_GPIO_ReadPin(GPIOF, GPIO_PIN_15) ;

	  	  if ((Read_SC_Fault == 0) || (Read_EARTH_Fault == 0))
	  	      {
	  		      PWM_stop();  //MCU stops PWM
	  	      }
//************************** SC & and Earth Protection for Motor ************************************

//		HAL_GPIO_WritePin(GPIOF, GPIO_PIN_7, GPIO_PIN_SET);
		pfc_cnt++;
	    pfc_control_run=1;

		if(enable_voltage_closed_loop)
			{
				runVDCramp();
			}
		else VdcRef=Vdc_filtered+10.0;

//		PE14 - IL
//		PB15 - Vac
//      PE8 - Vdc

		Vac_INT=ADC4_buffer[0]; //PB15 - ADC4IN5
		Vdc_INT=ADC4_buffer[1]; //PE8 - ADC4IN
		IL_INT=ADC4_buffer[2];  //PE14 - ADC4IN

		Vac=0.101779541f*(float)Vac_INT*Vac_calibration;
		IL=-0.0084817f*(float)(3760-IL_INT/*3072*/)*IL_calibration; // from PFC
		Vdc=0.109296892*(float)Vdc_INT*Vdc_calibration;

        //uncomment to enable protection

//    	if((IL < IL_Trip) && (enable_OCD == 1))   // OC and OV protection
//		{
//			PFC_PWM_stop();
//			enable_closed_loop=0;
//			enable_voltage_closed_loop=0;
//			// DemandCurrentMAX=9500.0;
//			CurrProtection_ON = 1;
//			PWM_stop();
//		}

//    	if((enable_OCD == 1) && (Vdc_filtered > Vdc_Trip))   // OC and OV protection
//		{
//			PFC_PWM_stop();
//			enable_closed_loop=0;
//			enable_voltage_closed_loop=0;
//			// DemandCurrentMAX=9500.0;
//			VolProtection_ON = 1;
//			PWM_stop();
//		}

//		if((enable_PFC_burst_mode) && (Protection_ON == 0)) // how did we make enable_PFC_burst_mode 1 ???
//		{
//		     PFC_PWM_start();
//			 enable_closed_loop=1;
//			 enable_voltage_closed_loop=1;
//		//	uncomment this for burst mode
//	        if (Vdc_filtered > Vburst_H)
//			    {
//				    PFC_PWM_stop();
//					enable_closed_loop=0;
//					enable_voltage_closed_loop=0;
//					ResetFilterDF22(&DCVoltageCompensator);
//					ResetFilterDF22(&CurrentCompensator);
//			    }
//
//		    if (Vdc_filtered < Vburst_L)
//		        {
//				     PFC_PWM_start();
//					 enable_closed_loop=1;
//					 enable_voltage_closed_loop=1;
//			  }
//		}

		if (pfc_control_run)
		    {
			    pfc_control_run=0;
	    		Vac_filtered=1.1f*RunFilterDF22(&testDF22filter,Vac);
	    		Vac_RMS=0.1*Vac_filtered*Vac_filtered+0.9*Vac_RMS;  // Vac_RMS is actually Vac_RMS^2
	    		Vdc_filtered=RunFilterDF22(&NotchFilter,Vdc);

	    		if(enable_voltage_closed_loop) IL_ref=DemandCurrent*Vac*VacPK_inv;
	    		else
	    		{
	    			IL_ref=Vary_Vc*Vac*VacPK_inv;
	    		}

	    		ei=(IL_ref+IL)*0.5;
	    		pfc_DC_control_run++;

	    		if(enable_closed_loop)
	    		    {
	    			pwm_cmd=RunFilterDF22(&CurrentCompensator,ei);// run current control compensator
	    			pwm_cmd_debug=pwm_cmd;
	    			if(pwm_cmd>0.95f)
	    			    {
	    				pwm_cmd=0.95f;
	    				CurrentCompensator.x2=CurrentCompensator.b2*ei-CurrentCompensator.a2*pwm_cmd;  //anti-wimdup
	    				CurrentCompensator.x1=CurrentCompensator.b1*ei-CurrentCompensator.a1*pwm_cmd+CurrentCompensator.x2;
	    			    }
	    			if(pwm_cmd<0.05f)
	    			    {
	    				pwm_cmd=0.05f;
	    				CurrentCompensator.x2=CurrentCompensator.b2*ei-CurrentCompensator.a2*pwm_cmd;  //anti-wimdup
	    				CurrentCompensator.x1=CurrentCompensator.b1*ei-CurrentCompensator.a1*pwm_cmd+CurrentCompensator.x2;
	    			    }
	    			pwm_cmd_uint=(uint16_t)(pwm_cmd*2297.0f);// use constant instead of 2125.0f

	    			if((pwm_cmd_uint<2182) && (pwm_cmd_uint>112)) __HAL_TIM_SetCompare(&htim3,TIM_CHANNEL_1,pwm_cmd_uint);
	    		}
	    		else
	    		{
	    			CurrentCompensator.x1=0.0f;
	    			CurrentCompensator.x2=0.0f;
//			    			pwm_cmd=0.05;
//			    			pwm_cmd_uint=112;
	    		}
	    		if(pfc_DC_control_run>=2)  // voltage loop
	    		{

	    			pfc_DC_control_run=0;
	    			ev=VdcRef-Vdc_filtered;

	    			if(enable_voltage_closed_loop)      // voltage loop
	    			{
	    				DemandCurrent=RunFilterDF22(&DCVoltageCompensator,ev);

						if(prot_var > 463)      //to delay the protection activation by 50ms
						{
						    enable_OCD = 1;
						    prot_var = 0;
						}
						prot_var ++ ;

	    				if(DemandCurrent>DemandCurrentMAX)
	    				{
	    					DemandCurrent=DemandCurrentMAX;
	    					DCVoltageCompensator.x2=DCVoltageCompensator.b2*ev-DCVoltageCompensator.a2*DemandCurrentMAX; //anti-windup
	    					DCVoltageCompensator.x1=DCVoltageCompensator.b1*ev-DCVoltageCompensator.a1*DemandCurrentMAX+DCVoltageCompensator.x2;
	    				}
	    				else if(DemandCurrent<100.0f)
	    				{
	    					DemandCurrent=100.0f;
	    					DCVoltageCompensator.x2=DCVoltageCompensator.b2*ev-DCVoltageCompensator.a2*100.0f;
	    					DCVoltageCompensator.x1=DCVoltageCompensator.b1*ev-DCVoltageCompensator.a1*100.0f+DCVoltageCompensator.x1;
	    				}
	    			}
	    			else
	    			{
	    			//	DCVoltageCompensator.x2=DCVoltageCompensator.b2*ev-DCVoltageCompensator.a2*Vc;
	    			//	DCVoltageCompensator.x1=DCVoltageCompensator.b1*ev-DCVoltageCompensator.a1*Vc+DCVoltageCompensator.x1;
	    			}

	    		}
	    }
//		HAL_GPIO_WritePin(GPIOF, GPIO_PIN_7, GPIO_PIN_RESET);
	}

	if (htim==&htim1)
	{
		pwm_cnt++;

		if (Enable == 1)
		{
//			HAL_GPIO_WritePin(GPIOF, GPIO_PIN_9, GPIO_PIN_SET);
			#if (MODE == MODE_1 || MODE == MODE_3 ||  MODE == MODE_5)      // Double Space Vector Modulation

			__HAL_TIM_SET_COMPARE(&htim1,TIM_CHANNEL_1,((HALF_TBPRD_PWM*svgen1.Ta)+HALF_TBPRD_PWM));
			__HAL_TIM_SET_COMPARE(&htim1,TIM_CHANNEL_2,((HALF_TBPRD_PWM*svgen1.Tb)+HALF_TBPRD_PWM));
			__HAL_TIM_SET_COMPARE(&htim1,TIM_CHANNEL_3,((HALF_TBPRD_PWM*svgen1.Tc)+HALF_TBPRD_PWM));

			__HAL_TIM_SET_COMPARE(&htim8,TIM_CHANNEL_1,((HALF_TBPRD_PWM*svgen2.Ta)+HALF_TBPRD_PWM));
			__HAL_TIM_SET_COMPARE(&htim8,TIM_CHANNEL_2,((HALF_TBPRD_PWM*svgen2.Tb)+HALF_TBPRD_PWM));
			__HAL_TIM_SET_COMPARE(&htim8,TIM_CHANNEL_3,((HALF_TBPRD_PWM*svgen2.Tc)+HALF_TBPRD_PWM));

		   #endif

			#if (MODE == MODE_2 || MODE == MODE_4 )      // VSD Modulation

			__HAL_TIM_SET_COMPARE(&htim1,TIM_CHANNEL_1,((HALF_TBPRD_PWM*ivsd1.As1)+HALF_TBPRD_PWM));
			__HAL_TIM_SET_COMPARE(&htim1,TIM_CHANNEL_2,((HALF_TBPRD_PWM*ivsd1.Bs1)+HALF_TBPRD_PWM));
			__HAL_TIM_SET_COMPARE(&htim1,TIM_CHANNEL_3,((HALF_TBPRD_PWM*ivsd1.Cs1)+HALF_TBPRD_PWM));

			__HAL_TIM_SET_COMPARE(&htim8,TIM_CHANNEL_1,((HALF_TBPRD_PWM*ivsd1.As2)+HALF_TBPRD_PWM));
			__HAL_TIM_SET_COMPARE(&htim8,TIM_CHANNEL_2,((HALF_TBPRD_PWM*ivsd1.Bs2)+HALF_TBPRD_PWM));
			__HAL_TIM_SET_COMPARE(&htim8,TIM_CHANNEL_3,((HALF_TBPRD_PWM*ivsd1.Cs2)+HALF_TBPRD_PWM));
		   #endif
//			HAL_GPIO_WritePin(GPIOF, GPIO_PIN_9, GPIO_PIN_RESET);

		}
		else

		{

			//PWM_stop();
			Reset_Controllers();
			rc1.SetpointValue = 0;

			__HAL_TIM_SET_COMPARE(&htim1,TIM_CHANNEL_1,0.0*TBPRD_PWM);
			__HAL_TIM_SET_COMPARE(&htim1,TIM_CHANNEL_2,0.0*TBPRD_PWM);
			__HAL_TIM_SET_COMPARE(&htim1,TIM_CHANNEL_3,0.0*TBPRD_PWM);

			__HAL_TIM_SET_COMPARE(&htim8,TIM_CHANNEL_1,0.0*TBPRD_PWM);
			__HAL_TIM_SET_COMPARE(&htim8,TIM_CHANNEL_2,0.0*TBPRD_PWM);
			__HAL_TIM_SET_COMPARE(&htim8,TIM_CHANNEL_3,0.0*TBPRD_PWM);

		}
		}
}

void Check_OCFault(void)
	  {

	     uint8_t i = 0, count_OCFault = 0;
		  for(i=0; i<6; i++)
		  {
			  Read_OC_Fault = HAL_GPIO_ReadPin(GPIOD, GPIO_PIN_1)     ;
		        if (Read_OC_Fault == 0)
		        {
		            count_OCFault++;
		        }
		        HAL_Delay(1); // optional, small delay between reads
		  }

		  if (count_OCFault >= 5)  // 5 out of 6
		      {
			      PWM_stop();
		          OCfault_Flag = 1;
		      }
		      else
		      {
		    	  OCfault_Flag = 0;
		    	  count_OCFault = 0;
		      }
	  }

void runVDCramp(void)
{

    if(VdcRef<(VdcTarget-dVref))
    {
    	VdcRef+=dVref*4;                                 // multiply by 4 due to reduction of loop frequency
    	/*if(DemandCurrentMAX<6000.0f)
    	{
    		DemandCurrentMAX+=0.07425f;
    	}*/
    }
    else if (VdcRef>(VdcTarget+dVref))
    {
    	VdcRef-=dVref;
    }
    else
    {
    	VdcRef=VdcTarget;
    	//VdcRampDone=1;
    }
    //HAL_GPIO_TogglePin(GPIOC, GPIO_PIN_8);
}

void PFC_PWM_start(void){
	HAL_TIM_PWM_Start(&htim3, TIM_CHANNEL_1);
}

void PFC_PWM_stop(void){
	HAL_TIM_PWM_Stop(&htim3, TIM_CHANNEL_1);
}

void UARTCommands()
{
	if (HAL_UART_Receive(&huart2, &received, sizeof(received), 10/*HAL_MAX_DELAY*/) == HAL_OK)
		  {
			  HAL_UART_Transmit(&huart2,&received,sizeof(received),10/*HAL_MAX_DELAY*/);

		  if(received=='e')                     // Enable PWM
		  {
			 PWM_start();
			 Enable = 1 ;
		  }
		  else if(received=='a')
		  {
			  Activate = 1.0 ;
		  }
		  else if(received=='s')  //stop PFC
		  {
			  PWM_stop();
			  user_freq = 0.0f;
			  mod_index = 0.0f;
			  PFC_PWM_stop();
			  enable_voltage_closed_loop = 0;
			  enable_closed_loop=0;
			  CurrProtection_ON = 0 ;
			  VolProtection_ON = 0 ;
			  DemandCurrentMAX = 1500;
		  }
//		  else if(received=='d')
//		  {
//			 dLogInt.status=1;
//			 trigger=2;
//			 dLogFloat.status=1;
//			 trigger_float=1;
//		  }
		  else if(received=='o')                     // Enable PFC PWM
		  {
			 PFC_PWM_start();
		  }
		  else if(received=='c')                     // Enable PFC PWM
		  {
			 enable_closed_loop=1;
		  }
		  else if(received == 'g')
		  {
			 enable_voltage_closed_loop = 1;
		  }
		  else if(received=='f')
		  {
			 freq_pu += 0.05; //pu
		  }
		  else if(received=='r')
		  {
			  freq_pu -= 0.05; //pu
		  }
		  else if(received=='m')
		  {
			  EM_Stop = 1;
		  }
		  else if(received=='i')
		  {
			  duty += 0.05; //pu
		  }
		  else if(received=='l')
		  {
			  duty -= 0.05; //pu
		  }
		  else if(received=='d')
		  {
			  IsRelayOn = 1; //pu
		  }
		  else if(received=='b')
		  {
			  IsRelayOn = 0; //pu
		  }
		  else if(received=='v')
		  {
			  Vary_Vc += 10.0; //pu
		  }
		  else if(received=='w')
		  {
			  Vary_Vc -= 10.0; //pu
		  }
		  else if(received=='t')
		  {
			  VdcTarget+=5.0 ;
		  }
		  else if(received=='u')
		  {
			  VdcTarget-=5.0 ;
		  }
		  else if(received=='x')
		  {
			  //DemandCurrentMAX += 100;
			  IdRef += 0.05;
		  }
		  else if(received=='y')
		  {
			  //DemandCurrentMAX -= 100;
			  IdRef -= 0.05;
		  }
		  }
}

/* USER CODE END 4 */

void Error_Handler(void)
{
  __disable_irq();
  while (1)
  {
  }
}
